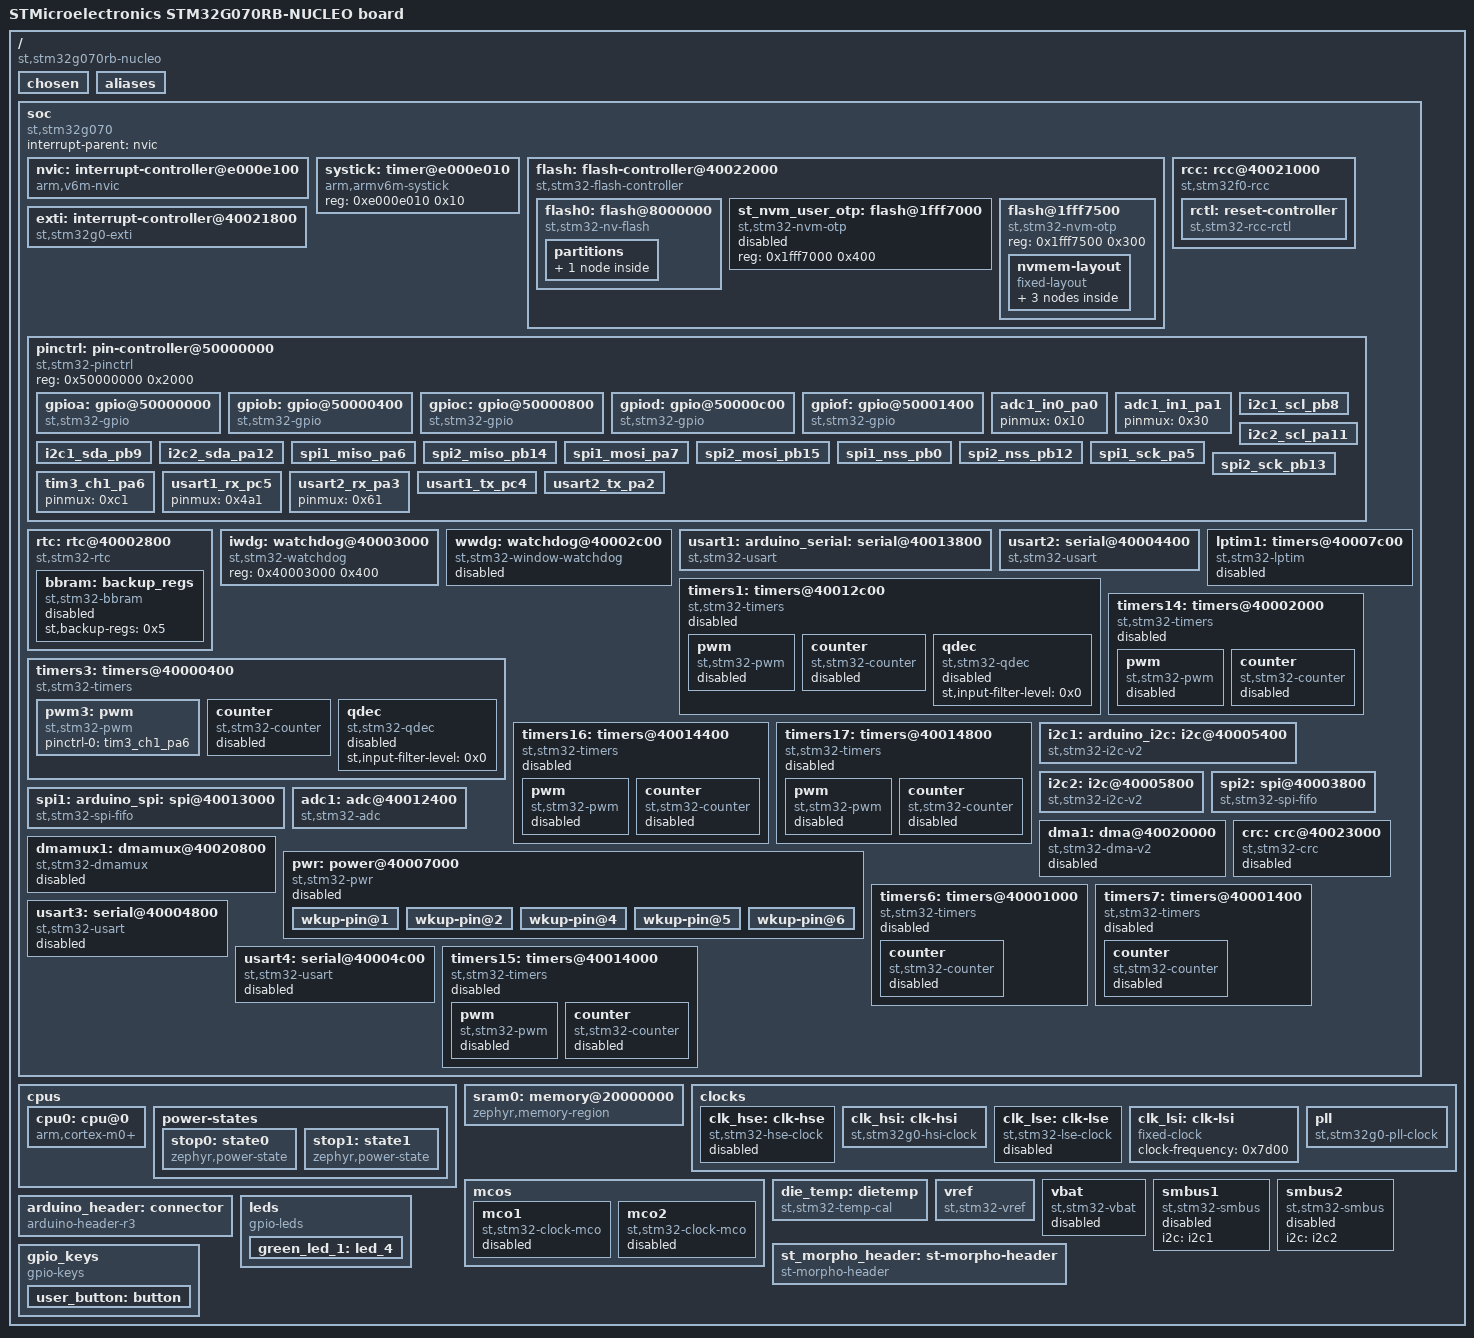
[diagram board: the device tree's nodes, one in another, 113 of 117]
/dts-v1/;

/* node '/' defined in zephyr\dts\common\skeleton.dtsi:9 */
/ {
	#address-cells = < 0x1 >;                              /* in zephyr\dts\common\skeleton.dtsi:10 */
	#size-cells = < 0x1 >;                                 /* in zephyr\dts\common\skeleton.dtsi:11 */
	model = "STMicroelectronics STM32G070RB-NUCLEO board"; /* in zephyr\boards\st\nucleo_g070rb\nucleo_g070rb.dts:15 */
	compatible = "st,stm32g070rb-nucleo";                  /* in zephyr\boards\st\nucleo_g070rb\nucleo_g070rb.dts:16 */

	/* node '/chosen' defined in zephyr\dts\common\skeleton.dtsi:13 */
	chosen {
		zephyr,crc = &crc;                /* in zephyr\dts\arm\st\g0\stm32g0.dtsi:27 */
		zephyr,flash-controller = &flash; /* in zephyr\dts\arm\st\g0\stm32g0.dtsi:28 */
		zephyr,console = &usart2;         /* in zephyr\boards\st\nucleo_g070rb\nucleo_g070rb.dts:19 */
		zephyr,shell-uart = &usart2;      /* in zephyr\boards\st\nucleo_g070rb\nucleo_g070rb.dts:20 */
		zephyr,sram = &sram0;             /* in zephyr\boards\st\nucleo_g070rb\nucleo_g070rb.dts:21 */
		zephyr,flash = &flash0;           /* in zephyr\boards\st\nucleo_g070rb\nucleo_g070rb.dts:22 */
	};

	/* node '/aliases' defined in zephyr\dts\common\skeleton.dtsi:15 */
	aliases {
		led0 = &green_led_1;   /* in zephyr\boards\st\nucleo_g070rb\nucleo_g070rb.dts:45 */
		sw0 = &user_button;    /* in zephyr\boards\st\nucleo_g070rb\nucleo_g070rb.dts:46 */
		watchdog0 = &iwdg;     /* in zephyr\boards\st\nucleo_g070rb\nucleo_g070rb.dts:47 */
		die-temp0 = &die_temp; /* in zephyr\boards\st\nucleo_g070rb\nucleo_g070rb.dts:48 */
		volt-sensor0 = &vref;  /* in zephyr\boards\st\nucleo_g070rb\nucleo_g070rb.dts:49 */
	};

	/* node '/soc' defined in zephyr\dts\arm\armv6-m.dtsi:6 */
	soc {
		#address-cells = < 0x1 >;     /* in zephyr\dts\arm\armv6-m.dtsi:7 */
		#size-cells = < 0x1 >;        /* in zephyr\dts\arm\armv6-m.dtsi:8 */
		interrupt-parent = < &nvic >; /* in zephyr\dts\arm\armv6-m.dtsi:10 */
		ranges;                       /* in zephyr\dts\arm\armv6-m.dtsi:11 */
		compatible = "st,stm32g070",
		             "st,stm32g0",
		             "simple-bus";    /* in zephyr\dts\arm\st\g0\stm32g070.dtsi:12 */

		/* node '/soc/interrupt-controller@e000e100' defined in zephyr\dts\arm\armv6-m.dtsi:13 */
		nvic: interrupt-controller@e000e100 {
			#address-cells = < 0x1 >;            /* in zephyr\dts\arm\armv6-m.dtsi:14 */
			compatible = "arm,v6m-nvic";         /* in zephyr\dts\arm\armv6-m.dtsi:15 */
			reg = < 0xe000e100 0xc00 >;          /* in zephyr\dts\arm\armv6-m.dtsi:16 */
			interrupt-controller;                /* in zephyr\dts\arm\armv6-m.dtsi:17 */
			#interrupt-cells = < 0x2 >;          /* in zephyr\dts\arm\armv6-m.dtsi:18 */
			arm,num-irq-priority-bits = < 0x2 >; /* in zephyr\dts\arm\st\g0\stm32g0.dtsi:623 */
			phandle = < 0x1 >;                   /* in zephyr\dts\arm\armv6-m.dtsi:10 */
		};

		/* node '/soc/timer@e000e010' defined in zephyr\dts\arm\armv6-m.dtsi:21 */
		systick: timer@e000e010 {
			compatible = "arm,armv6m-systick"; /* in zephyr\dts\arm\armv6-m.dtsi:22 */
			reg = < 0xe000e010 0x10 >;         /* in zephyr\dts\arm\armv6-m.dtsi:23 */
		};

		/* node '/soc/flash-controller@40022000' defined in zephyr\dts\arm\st\g0\stm32g0.dtsi:116 */
		flash: flash-controller@40022000 {
			compatible = "st,stm32-flash-controller",
			             "st,stm32g0-flash-controller"; /* in zephyr\dts\arm\st\g0\stm32g0.dtsi:117 */
			reg = < 0x40022000 0x400 >;                 /* in zephyr\dts\arm\st\g0\stm32g0.dtsi:118 */
			interrupts = < 0x3 0x0 >;                   /* in zephyr\dts\arm\st\g0\stm32g0.dtsi:119 */
			clocks = < &rcc 0x38 0x100 >;               /* in zephyr\dts\arm\st\g0\stm32g0.dtsi:120 */
			#address-cells = < 0x1 >;                   /* in zephyr\dts\arm\st\g0\stm32g0.dtsi:122 */
			#size-cells = < 0x1 >;                      /* in zephyr\dts\arm\st\g0\stm32g0.dtsi:123 */
			ranges;                                     /* in zephyr\dts\arm\st\g0\stm32g0.dtsi:124 */

			/* node '/soc/flash-controller@40022000/flash@8000000' defined in zephyr\dts\arm\st\g0\stm32g0.dtsi:126 */
			flash0: flash@8000000 {
				compatible = "st,stm32-nv-flash",
				             "soc-nv-flash";        /* in zephyr\dts\arm\st\g0\stm32g0.dtsi:127 */
				#address-cells = < 0x1 >;           /* in zephyr\dts\arm\st\g0\stm32g0.dtsi:128 */
				#size-cells = < 0x1 >;              /* in zephyr\dts\arm\st\g0\stm32g0.dtsi:129 */
				write-block-size = < 0x8 >;         /* in zephyr\dts\arm\st\g0\stm32g0.dtsi:130 */
				erase-block-size = < 0x800 >;       /* in zephyr\dts\arm\st\g0\stm32g0.dtsi:131 */
				max-erase-time = < 0x28 >;          /* in zephyr\dts\arm\st\g0\stm32g0.dtsi:133 */
				reg = < 0x8000000 0x20000 >;        /* in zephyr\dts\arm\st\g0\stm32g070Xb.dtsi:18 */
				ranges = < 0x0 0x8000000 0x20000 >; /* in zephyr\dts\arm\st\g0\stm32g070Xb.dtsi:19 */

				/* node '/soc/flash-controller@40022000/flash@8000000/partitions' defined in zephyr\boards\st\nucleo_g070rb\nucleo_g070rb.dts:159 */
				partitions {
					#address-cells = < 0x1 >; /* in zephyr\boards\st\nucleo_g070rb\nucleo_g070rb.dts:160 */
					#size-cells = < 0x1 >;    /* in zephyr\boards\st\nucleo_g070rb\nucleo_g070rb.dts:161 */
					ranges;                   /* in zephyr\boards\st\nucleo_g070rb\nucleo_g070rb.dts:162 */

					/* node '/soc/flash-controller@40022000/flash@8000000/partitions/partition@1f000' defined in zephyr\boards\st\nucleo_g070rb\nucleo_g070rb.dts:165 */
					storage_partition: partition@1f000 {
						compatible = "zephyr,mapped-partition"; /* in zephyr\boards\st\nucleo_g070rb\nucleo_g070rb.dts:166 */
						label = "storage";                      /* in zephyr\boards\st\nucleo_g070rb\nucleo_g070rb.dts:167 */
						reg = < 0x1f000 0x1000 >;               /* in zephyr\boards\st\nucleo_g070rb\nucleo_g070rb.dts:168 */
					};
				};
			};

			/* node '/soc/flash-controller@40022000/flash@1fff7000' defined in zephyr\dts\arm\st\g0\stm32g0.dtsi:136 */
			st_nvm_user_otp: flash@1fff7000 {
				compatible = "st,stm32-nvm-otp"; /* in zephyr\dts\arm\st\g0\stm32g0.dtsi:137 */
				reg = < 0x1fff7000 0x400 >;      /* in zephyr\dts\arm\st\g0\stm32g0.dtsi:138 */
				status = "disabled";             /* in zephyr\dts\arm\st\g0\stm32g0.dtsi:139 */
			};

			/* node '/soc/flash-controller@40022000/flash@1fff7500' defined in zephyr\dts\arm\st\g0\stm32g0.dtsi:143 */
			flash@1fff7500 {
				compatible = "st,stm32-nvm-otp"; /* in zephyr\dts\arm\st\g0\stm32g0.dtsi:144 */
				reg = < 0x1fff7500 0x300 >;      /* in zephyr\dts\arm\st\g0\stm32g0.dtsi:145 */

				/* node '/soc/flash-controller@40022000/flash@1fff7500/nvmem-layout' defined in zephyr\dts\arm\st\g0\stm32g0.dtsi:147 */
				nvmem-layout {
					compatible = "fixed-layout"; /* in zephyr\dts\arm\st\g0\stm32g0.dtsi:148 */
					#address-cells = < 0x1 >;    /* in zephyr\dts\arm\st\g0\stm32g0.dtsi:149 */
					#size-cells = < 0x1 >;       /* in zephyr\dts\arm\st\g0\stm32g0.dtsi:150 */

					/* node '/soc/flash-controller@40022000/flash@1fff7500/nvmem-layout/ts-cal1@a8' defined in zephyr\dts\arm\st\g0\stm32g0.dtsi:152 */
					ts_cal1_otp: ts-cal1@a8 {
						reg = < 0xa8 0x2 >;          /* in zephyr\dts\arm\st\g0\stm32g0.dtsi:153 */
						#nvmem-cell-cells = < 0x0 >; /* in zephyr\dts\arm\st\g0\stm32g0.dtsi:154 */
						read-only;                   /* in zephyr\dts\arm\st\g0\stm32g0.dtsi:155 */
						phandle = < 0x1e >;          /* in zephyr\dts\arm\st\g0\stm32g0.dtsi:581 */
					};

					/* node '/soc/flash-controller@40022000/flash@1fff7500/nvmem-layout/vrefint@aa' defined in zephyr\dts\arm\st\g0\stm32g0.dtsi:158 */
					vrefint_otp: vrefint@aa {
						reg = < 0xaa 0x2 >;          /* in zephyr\dts\arm\st\g0\stm32g0.dtsi:159 */
						#nvmem-cell-cells = < 0x0 >; /* in zephyr\dts\arm\st\g0\stm32g0.dtsi:160 */
						read-only;                   /* in zephyr\dts\arm\st\g0\stm32g0.dtsi:161 */
						phandle = < 0x21 >;          /* in zephyr\dts\arm\st\g0\stm32g0.dtsi:592 */
					};

					/* node '/soc/flash-controller@40022000/flash@1fff7500/nvmem-layout/ts-cal2@ca' defined in zephyr\dts\arm\st\g0\stm32g0.dtsi:164 */
					ts_cal2_otp: ts-cal2@ca {
						reg = < 0xca 0x2 >;          /* in zephyr\dts\arm\st\g0\stm32g0.dtsi:165 */
						#nvmem-cell-cells = < 0x0 >; /* in zephyr\dts\arm\st\g0\stm32g0.dtsi:166 */
						read-only;                   /* in zephyr\dts\arm\st\g0\stm32g0.dtsi:167 */
						phandle = < 0x1f >;          /* in zephyr\dts\arm\st\g0\stm32g0.dtsi:581 */
					};
				};
			};
		};

		/* node '/soc/rcc@40021000' defined in zephyr\dts\arm\st\g0\stm32g0.dtsi:173 */
		rcc: rcc@40021000 {
			compatible = "st,stm32f0-rcc";   /* in zephyr\dts\arm\st\g0\stm32g0.dtsi:174 */
			#clock-cells = < 0x2 >;          /* in zephyr\dts\arm\st\g0\stm32g0.dtsi:175 */
			reg = < 0x40021000 0x400 >;      /* in zephyr\dts\arm\st\g0\stm32g0.dtsi:176 */
			clocks = < &pll >;               /* in zephyr\boards\st\nucleo_g070rb\nucleo_g070rb.dts:71 */
			clock-frequency = < 0x3d09000 >; /* in zephyr\boards\st\nucleo_g070rb\nucleo_g070rb.dts:72 */
			ahb-prescaler = < 0x1 >;         /* in zephyr\boards\st\nucleo_g070rb\nucleo_g070rb.dts:73 */
			apb1-prescaler = < 0x1 >;        /* in zephyr\boards\st\nucleo_g070rb\nucleo_g070rb.dts:74 */
			phandle = < 0x2 >;               /* in zephyr\dts\arm\st\g0\stm32g0.dtsi:120 */

			/* node '/soc/rcc@40021000/reset-controller' defined in zephyr\dts\arm\st\g0\stm32g0.dtsi:178 */
			rctl: reset-controller {
				compatible = "st,stm32-rcc-rctl"; /* in zephyr\dts\arm\st\g0\stm32g0.dtsi:179 */
				#reset-cells = < 0x1 >;           /* in zephyr\dts\arm\st\g0\stm32g0.dtsi:180 */
				phandle = < 0x4 >;                /* in zephyr\dts\arm\st\g0\stm32g0.dtsi:285 */
			};
		};

		/* node '/soc/interrupt-controller@40021800' defined in zephyr\dts\arm\st\g0\stm32g0.dtsi:184 */
		exti: interrupt-controller@40021800 {
			compatible = "st,stm32g0-exti",
			             "st,stm32-exti";   /* in zephyr\dts\arm\st\g0\stm32g0.dtsi:185 */
			interrupt-controller;           /* in zephyr\dts\arm\st\g0\stm32g0.dtsi:186 */
			#interrupt-cells = < 0x1 >;     /* in zephyr\dts\arm\st\g0\stm32g0.dtsi:187 */
			#address-cells = < 0x0 >;       /* in zephyr\dts\arm\st\g0\stm32g0.dtsi:188 */
			reg = < 0x40021800 0x400 >;     /* in zephyr\dts\arm\st\g0\stm32g0.dtsi:189 */
			clocks = < &rcc 0x40 0x1 >;     /* in zephyr\dts\arm\st\g0\stm32g0.dtsi:190 */
			num-lines = < 0x20 >;           /* in zephyr\dts\arm\st\g0\stm32g0.dtsi:191 */
			interrupts = < 0x5 0x0 >,
			             < 0x6 0x0 >,
			             < 0x7 0x0 >;       /* in zephyr\dts\arm\st\g0\stm32g0.dtsi:192 */
			interrupt-names = "line0-1",
			                  "line2-3",
			                  "line4-15";   /* in zephyr\dts\arm\st\g0\stm32g0.dtsi:193 */
			line-ranges = < 0x0 0x2 >,
			              < 0x2 0x2 >,
			              < 0x4 0xc >;      /* in zephyr\dts\arm\st\g0\stm32g0.dtsi:194 */
		};

		/* node '/soc/pin-controller@50000000' defined in zephyr\dts\arm\st\g0\stm32g0.dtsi:197 */
		pinctrl: pin-controller@50000000 {
			compatible = "st,stm32-pinctrl"; /* in zephyr\dts\arm\st\g0\stm32g0.dtsi:198 */
			#address-cells = < 0x1 >;        /* in zephyr\dts\arm\st\g0\stm32g0.dtsi:199 */
			#size-cells = < 0x1 >;           /* in zephyr\dts\arm\st\g0\stm32g0.dtsi:200 */
			reg = < 0x50000000 0x2000 >;     /* in zephyr\dts\arm\st\g0\stm32g0.dtsi:201 */

			/* node '/soc/pin-controller@50000000/gpio@50000000' defined in zephyr\dts\arm\st\g0\stm32g0.dtsi:203 */
			gpioa: gpio@50000000 {
				compatible = "st,stm32-gpio"; /* in zephyr\dts\arm\st\g0\stm32g0.dtsi:204 */
				gpio-controller;              /* in zephyr\dts\arm\st\g0\stm32g0.dtsi:205 */
				#gpio-cells = < 0x2 >;        /* in zephyr\dts\arm\st\g0\stm32g0.dtsi:206 */
				reg = < 0x50000000 0x400 >;   /* in zephyr\dts\arm\st\g0\stm32g0.dtsi:207 */
				clocks = < &rcc 0x34 0x1 >;   /* in zephyr\dts\arm\st\g0\stm32g0.dtsi:208 */
				phandle = < 0xf >;            /* in zephyr\boards\st\nucleo_g070rb\nucleo_g070rb.dts:125 */
			};

			/* node '/soc/pin-controller@50000000/gpio@50000400' defined in zephyr\dts\arm\st\g0\stm32g0.dtsi:211 */
			gpiob: gpio@50000400 {
				compatible = "st,stm32-gpio"; /* in zephyr\dts\arm\st\g0\stm32g0.dtsi:212 */
				gpio-controller;              /* in zephyr\dts\arm\st\g0\stm32g0.dtsi:213 */
				#gpio-cells = < 0x2 >;        /* in zephyr\dts\arm\st\g0\stm32g0.dtsi:214 */
				reg = < 0x50000400 0x400 >;   /* in zephyr\dts\arm\st\g0\stm32g0.dtsi:215 */
				clocks = < &rcc 0x34 0x2 >;   /* in zephyr\dts\arm\st\g0\stm32g0.dtsi:216 */
				phandle = < 0xc >;            /* in zephyr\boards\st\nucleo_g070rb\nucleo_g070rb.dts:116 */
			};

			/* node '/soc/pin-controller@50000000/gpio@50000800' defined in zephyr\dts\arm\st\g0\stm32g0.dtsi:219 */
			gpioc: gpio@50000800 {
				compatible = "st,stm32-gpio"; /* in zephyr\dts\arm\st\g0\stm32g0.dtsi:220 */
				gpio-controller;              /* in zephyr\dts\arm\st\g0\stm32g0.dtsi:221 */
				#gpio-cells = < 0x2 >;        /* in zephyr\dts\arm\st\g0\stm32g0.dtsi:222 */
				reg = < 0x50000800 0x400 >;   /* in zephyr\dts\arm\st\g0\stm32g0.dtsi:223 */
				clocks = < &rcc 0x34 0x4 >;   /* in zephyr\dts\arm\st\g0\stm32g0.dtsi:224 */
				phandle = < 0x1a >;           /* in zephyr\dts\arm\st\g0\stm32g0.dtsi:548 */
			};

			/* node '/soc/pin-controller@50000000/gpio@50000c00' defined in zephyr\dts\arm\st\g0\stm32g0.dtsi:227 */
			gpiod: gpio@50000c00 {
				compatible = "st,stm32-gpio"; /* in zephyr\dts\arm\st\g0\stm32g0.dtsi:228 */
				gpio-controller;              /* in zephyr\dts\arm\st\g0\stm32g0.dtsi:229 */
				#gpio-cells = < 0x2 >;        /* in zephyr\dts\arm\st\g0\stm32g0.dtsi:230 */
				reg = < 0x50000c00 0x400 >;   /* in zephyr\dts\arm\st\g0\stm32g0.dtsi:231 */
				clocks = < &rcc 0x34 0x8 >;   /* in zephyr\dts\arm\st\g0\stm32g0.dtsi:232 */
				phandle = < 0x24 >;           /* in zephyr\boards\st\nucleo_g070rb\st_morpho_connector.dtsi:15 */
			};

			/* node '/soc/pin-controller@50000000/gpio@50001400' defined in zephyr\dts\arm\st\g0\stm32g0.dtsi:235 */
			gpiof: gpio@50001400 {
				compatible = "st,stm32-gpio"; /* in zephyr\dts\arm\st\g0\stm32g0.dtsi:236 */
				gpio-controller;              /* in zephyr\dts\arm\st\g0\stm32g0.dtsi:237 */
				#gpio-cells = < 0x2 >;        /* in zephyr\dts\arm\st\g0\stm32g0.dtsi:238 */
				reg = < 0x50001400 0x400 >;   /* in zephyr\dts\arm\st\g0\stm32g0.dtsi:239 */
				clocks = < &rcc 0x34 0x20 >;  /* in zephyr\dts\arm\st\g0\stm32g0.dtsi:240 */
				phandle = < 0x25 >;           /* in zephyr\boards\st\nucleo_g070rb\st_morpho_connector.dtsi:15 */
			};

			/* node '/soc/pin-controller@50000000/adc1_in0_pa0' defined in modules\hal\stm32\dts\st\g0\stm32g070rbtx-pinctrl.dtsi:13 */
			adc1_in0_pa0: adc1_in0_pa0 {
				pinmux = < 0x10 >;  /* in modules\hal\stm32\dts\st\g0\stm32g070rbtx-pinctrl.dtsi:14 */
				phandle = < 0x18 >; /* in zephyr\boards\st\nucleo_g070rb\nucleo_g070rb.dts:146 */
			};

			/* node '/soc/pin-controller@50000000/adc1_in1_pa1' defined in modules\hal\stm32\dts\st\g0\stm32g070rbtx-pinctrl.dtsi:17 */
			adc1_in1_pa1: adc1_in1_pa1 {
				pinmux = < 0x30 >;  /* in modules\hal\stm32\dts\st\g0\stm32g070rbtx-pinctrl.dtsi:18 */
				phandle = < 0x19 >; /* in zephyr\boards\st\nucleo_g070rb\nucleo_g070rb.dts:146 */
			};

			/* node '/soc/pin-controller@50000000/i2c1_scl_pb8' defined in modules\hal\stm32\dts\st\g0\stm32g070rbtx-pinctrl.dtsi:329 */
			i2c1_scl_pb8: i2c1_scl_pb8 {
				pinmux = < 0x306 >; /* in modules\hal\stm32\dts\st\g0\stm32g070rbtx-pinctrl.dtsi:330 */
				bias-pull-up;       /* in modules\hal\stm32\dts\st\g0\stm32g070rbtx-pinctrl.dtsi:331 */
				drive-open-drain;   /* in modules\hal\stm32\dts\st\g0\stm32g070rbtx-pinctrl.dtsi:332 */
				phandle = < 0xa >;  /* in zephyr\boards\st\nucleo_g070rb\nucleo_g070rb.dts:114 */
			};

			/* node '/soc/pin-controller@50000000/i2c2_scl_pa11' defined in modules\hal\stm32\dts\st\g0\stm32g070rbtx-pinctrl.dtsi:335 */
			i2c2_scl_pa11: i2c2_scl_pa11 {
				pinmux = < 0x166 >; /* in modules\hal\stm32\dts\st\g0\stm32g070rbtx-pinctrl.dtsi:336 */
				bias-pull-up;       /* in modules\hal\stm32\dts\st\g0\stm32g070rbtx-pinctrl.dtsi:337 */
				drive-open-drain;   /* in modules\hal\stm32\dts\st\g0\stm32g070rbtx-pinctrl.dtsi:338 */
				phandle = < 0xd >;  /* in zephyr\boards\st\nucleo_g070rb\nucleo_g070rb.dts:123 */
			};

			/* node '/soc/pin-controller@50000000/i2c1_sda_pb9' defined in modules\hal\stm32\dts\st\g0\stm32g070rbtx-pinctrl.dtsi:367 */
			i2c1_sda_pb9: i2c1_sda_pb9 {
				pinmux = < 0x326 >; /* in modules\hal\stm32\dts\st\g0\stm32g070rbtx-pinctrl.dtsi:368 */
				bias-pull-up;       /* in modules\hal\stm32\dts\st\g0\stm32g070rbtx-pinctrl.dtsi:369 */
				drive-open-drain;   /* in modules\hal\stm32\dts\st\g0\stm32g070rbtx-pinctrl.dtsi:370 */
				phandle = < 0xb >;  /* in zephyr\boards\st\nucleo_g070rb\nucleo_g070rb.dts:114 */
			};

			/* node '/soc/pin-controller@50000000/i2c2_sda_pa12' defined in modules\hal\stm32\dts\st\g0\stm32g070rbtx-pinctrl.dtsi:373 */
			i2c2_sda_pa12: i2c2_sda_pa12 {
				pinmux = < 0x186 >; /* in modules\hal\stm32\dts\st\g0\stm32g070rbtx-pinctrl.dtsi:374 */
				bias-pull-up;       /* in modules\hal\stm32\dts\st\g0\stm32g070rbtx-pinctrl.dtsi:375 */
				drive-open-drain;   /* in modules\hal\stm32\dts\st\g0\stm32g070rbtx-pinctrl.dtsi:376 */
				phandle = < 0xe >;  /* in zephyr\boards\st\nucleo_g070rb\nucleo_g070rb.dts:123 */
			};

			/* node '/soc/pin-controller@50000000/spi1_miso_pa6' defined in modules\hal\stm32\dts\st\g0\stm32g070rbtx-pinctrl.dtsi:511 */
			spi1_miso_pa6: spi1_miso_pa6 {
				pinmux = < 0xc0 >;             /* in modules\hal\stm32\dts\st\g0\stm32g070rbtx-pinctrl.dtsi:512 */
				bias-pull-down;                /* in modules\hal\stm32\dts\st\g0\stm32g070rbtx-pinctrl.dtsi:513 */
				slew-rate = "very-high-speed"; /* in modules\hal\stm32\dts\st\g0\stm32g070rbtx-pinctrl.dtsi:514 */
				phandle = < 0x12 >;            /* in zephyr\boards\st\nucleo_g070rb\nucleo_g070rb.dts:132 */
			};

			/* node '/soc/pin-controller@50000000/spi2_miso_pb14' defined in modules\hal\stm32\dts\st\g0\stm32g070rbtx-pinctrl.dtsi:559 */
			spi2_miso_pb14: spi2_miso_pb14 {
				pinmux = < 0x3c0 >;            /* in modules\hal\stm32\dts\st\g0\stm32g070rbtx-pinctrl.dtsi:560 */
				bias-pull-down;                /* in modules\hal\stm32\dts\st\g0\stm32g070rbtx-pinctrl.dtsi:561 */
				slew-rate = "very-high-speed"; /* in modules\hal\stm32\dts\st\g0\stm32g070rbtx-pinctrl.dtsi:562 */
				phandle = < 0x16 >;            /* in zephyr\boards\st\nucleo_g070rb\nucleo_g070rb.dts:139 */
			};

			/* node '/soc/pin-controller@50000000/spi1_mosi_pa7' defined in modules\hal\stm32\dts\st\g0\stm32g070rbtx-pinctrl.dtsi:585 */
			spi1_mosi_pa7: spi1_mosi_pa7 {
				pinmux = < 0xe0 >;             /* in modules\hal\stm32\dts\st\g0\stm32g070rbtx-pinctrl.dtsi:586 */
				bias-pull-down;                /* in modules\hal\stm32\dts\st\g0\stm32g070rbtx-pinctrl.dtsi:587 */
				slew-rate = "very-high-speed"; /* in modules\hal\stm32\dts\st\g0\stm32g070rbtx-pinctrl.dtsi:588 */
				phandle = < 0x13 >;            /* in zephyr\boards\st\nucleo_g070rb\nucleo_g070rb.dts:132 */
			};

			/* node '/soc/pin-controller@50000000/spi2_mosi_pb15' defined in modules\hal\stm32\dts\st\g0\stm32g070rbtx-pinctrl.dtsi:633 */
			spi2_mosi_pb15: spi2_mosi_pb15 {
				pinmux = < 0x3e0 >;            /* in modules\hal\stm32\dts\st\g0\stm32g070rbtx-pinctrl.dtsi:634 */
				bias-pull-down;                /* in modules\hal\stm32\dts\st\g0\stm32g070rbtx-pinctrl.dtsi:635 */
				slew-rate = "very-high-speed"; /* in modules\hal\stm32\dts\st\g0\stm32g070rbtx-pinctrl.dtsi:636 */
				phandle = < 0x17 >;            /* in zephyr\boards\st\nucleo_g070rb\nucleo_g070rb.dts:139 */
			};

			/* node '/soc/pin-controller@50000000/spi1_nss_pb0' defined in modules\hal\stm32\dts\st\g0\stm32g070rbtx-pinctrl.dtsi:665 */
			spi1_nss_pb0: spi1_nss_pb0 {
				pinmux = < 0x200 >;            /* in modules\hal\stm32\dts\st\g0\stm32g070rbtx-pinctrl.dtsi:666 */
				bias-pull-up;                  /* in modules\hal\stm32\dts\st\g0\stm32g070rbtx-pinctrl.dtsi:667 */
				slew-rate = "very-high-speed"; /* in modules\hal\stm32\dts\st\g0\stm32g070rbtx-pinctrl.dtsi:668 */
				phandle = < 0x10 >;            /* in zephyr\boards\st\nucleo_g070rb\nucleo_g070rb.dts:132 */
			};

			/* node '/soc/pin-controller@50000000/spi2_nss_pb12' defined in modules\hal\stm32\dts\st\g0\stm32g070rbtx-pinctrl.dtsi:689 */
			spi2_nss_pb12: spi2_nss_pb12 {
				pinmux = < 0x380 >;            /* in modules\hal\stm32\dts\st\g0\stm32g070rbtx-pinctrl.dtsi:690 */
				bias-pull-up;                  /* in modules\hal\stm32\dts\st\g0\stm32g070rbtx-pinctrl.dtsi:691 */
				slew-rate = "very-high-speed"; /* in modules\hal\stm32\dts\st\g0\stm32g070rbtx-pinctrl.dtsi:692 */
				phandle = < 0x14 >;            /* in zephyr\boards\st\nucleo_g070rb\nucleo_g070rb.dts:139 */
			};

			/* node '/soc/pin-controller@50000000/spi1_sck_pa5' defined in modules\hal\stm32\dts\st\g0\stm32g070rbtx-pinctrl.dtsi:709 */
			spi1_sck_pa5: spi1_sck_pa5 {
				pinmux = < 0xa0 >;             /* in modules\hal\stm32\dts\st\g0\stm32g070rbtx-pinctrl.dtsi:710 */
				bias-pull-down;                /* in modules\hal\stm32\dts\st\g0\stm32g070rbtx-pinctrl.dtsi:711 */
				slew-rate = "very-high-speed"; /* in modules\hal\stm32\dts\st\g0\stm32g070rbtx-pinctrl.dtsi:712 */
				phandle = < 0x11 >;            /* in zephyr\boards\st\nucleo_g070rb\nucleo_g070rb.dts:132 */
			};

			/* node '/soc/pin-controller@50000000/spi2_sck_pb13' defined in modules\hal\stm32\dts\st\g0\stm32g070rbtx-pinctrl.dtsi:745 */
			spi2_sck_pb13: spi2_sck_pb13 {
				pinmux = < 0x3a0 >;            /* in modules\hal\stm32\dts\st\g0\stm32g070rbtx-pinctrl.dtsi:746 */
				bias-pull-down;                /* in modules\hal\stm32\dts\st\g0\stm32g070rbtx-pinctrl.dtsi:747 */
				slew-rate = "very-high-speed"; /* in modules\hal\stm32\dts\st\g0\stm32g070rbtx-pinctrl.dtsi:748 */
				phandle = < 0x15 >;            /* in zephyr\boards\st\nucleo_g070rb\nucleo_g070rb.dts:139 */
			};

			/* node '/soc/pin-controller@50000000/tim3_ch1_pa6' defined in modules\hal\stm32\dts\st\g0\stm32g070rbtx-pinctrl.dtsi:835 */
			tim3_ch1_pa6: tim3_ch1_pa6 {
				pinmux = < 0xc1 >; /* in modules\hal\stm32\dts\st\g0\stm32g070rbtx-pinctrl.dtsi:836 */
				phandle = < 0x9 >; /* in zephyr\boards\st\nucleo_g070rb\nucleo_g070rb.dts:108 */
			};

			/* node '/soc/pin-controller@50000000/usart1_rx_pc5' defined in modules\hal\stm32\dts\st\g0\stm32g070rbtx-pinctrl.dtsi:1108 */
			usart1_rx_pc5: usart1_rx_pc5 {
				pinmux = < 0x4a1 >; /* in modules\hal\stm32\dts\st\g0\stm32g070rbtx-pinctrl.dtsi:1109 */
				phandle = < 0x6 >;  /* in zephyr\boards\st\nucleo_g070rb\nucleo_g070rb.dts:78 */
			};

			/* node '/soc/pin-controller@50000000/usart2_rx_pa3' defined in modules\hal\stm32\dts\st\g0\stm32g070rbtx-pinctrl.dtsi:1112 */
			usart2_rx_pa3: usart2_rx_pa3 {
				pinmux = < 0x61 >; /* in modules\hal\stm32\dts\st\g0\stm32g070rbtx-pinctrl.dtsi:1113 */
				phandle = < 0x8 >; /* in zephyr\boards\st\nucleo_g070rb\nucleo_g070rb.dts:85 */
			};

			/* node '/soc/pin-controller@50000000/usart1_tx_pc4' defined in modules\hal\stm32\dts\st\g0\stm32g070rbtx-pinctrl.dtsi:1168 */
			usart1_tx_pc4: usart1_tx_pc4 {
				pinmux = < 0x481 >; /* in modules\hal\stm32\dts\st\g0\stm32g070rbtx-pinctrl.dtsi:1169 */
				bias-pull-up;       /* in modules\hal\stm32\dts\st\g0\stm32g070rbtx-pinctrl.dtsi:1170 */
				phandle = < 0x5 >;  /* in zephyr\boards\st\nucleo_g070rb\nucleo_g070rb.dts:78 */
			};

			/* node '/soc/pin-controller@50000000/usart2_tx_pa2' defined in modules\hal\stm32\dts\st\g0\stm32g070rbtx-pinctrl.dtsi:1173 */
			usart2_tx_pa2: usart2_tx_pa2 {
				pinmux = < 0x41 >; /* in modules\hal\stm32\dts\st\g0\stm32g070rbtx-pinctrl.dtsi:1174 */
				bias-pull-up;      /* in modules\hal\stm32\dts\st\g0\stm32g070rbtx-pinctrl.dtsi:1175 */
				phandle = < 0x7 >; /* in zephyr\boards\st\nucleo_g070rb\nucleo_g070rb.dts:85 */
			};
		};

		/* node '/soc/rtc@40002800' defined in zephyr\dts\arm\st\g0\stm32g0.dtsi:244 */
		rtc: rtc@40002800 {
			compatible = "st,stm32-rtc";     /* in zephyr\dts\arm\st\g0\stm32g0.dtsi:245 */
			reg = < 0x40002800 0x400 >;      /* in zephyr\dts\arm\st\g0\stm32g0.dtsi:246 */
			interrupts = < 0x2 0x0 >;        /* in zephyr\dts\arm\st\g0\stm32g0.dtsi:247 */
			prescaler = < 0x8000 >;          /* in zephyr\dts\arm\st\g0\stm32g0.dtsi:249 */
			alarms-count = < 0x2 >;          /* in zephyr\dts\arm\st\g0\stm32g0.dtsi:250 */
			alrm-exti-line = < 0x13 >;       /* in zephyr\dts\arm\st\g0\stm32g0.dtsi:251 */
			clocks = < &rcc 0x3c 0x400 >,
			         < &rcc 0x3 0x228005c >; /* in zephyr\boards\st\nucleo_g070rb\nucleo_g070rb.dts:92 */
			status = "okay";                 /* in zephyr\boards\st\nucleo_g070rb\nucleo_g070rb.dts:95 */

			/* node '/soc/rtc@40002800/backup_regs' defined in zephyr\dts\arm\st\g0\stm32g0.dtsi:260 */
			bbram: backup_regs {
				compatible = "st,stm32-bbram"; /* in zephyr\dts\arm\st\g0\stm32g0.dtsi:261 */
				st,backup-regs = < 0x5 >;      /* in zephyr\dts\arm\st\g0\stm32g0.dtsi:262 */
				status = "disabled";           /* in zephyr\dts\arm\st\g0\stm32g0.dtsi:263 */
			};
		};

		/* node '/soc/watchdog@40003000' defined in zephyr\dts\arm\st\g0\stm32g0.dtsi:267 */
		iwdg: watchdog@40003000 {
			compatible = "st,stm32-watchdog"; /* in zephyr\dts\arm\st\g0\stm32g0.dtsi:268 */
			reg = < 0x40003000 0x400 >;       /* in zephyr\dts\arm\st\g0\stm32g0.dtsi:269 */
			status = "okay";                  /* in zephyr\boards\st\nucleo_g070rb\nucleo_g070rb.dts:99 */
		};

		/* node '/soc/watchdog@40002c00' defined in zephyr\dts\arm\st\g0\stm32g0.dtsi:273 */
		wwdg: watchdog@40002c00 {
			compatible = "st,stm32-window-watchdog"; /* in zephyr\dts\arm\st\g0\stm32g0.dtsi:274 */
			reg = < 0x40002c00 0x400 >;              /* in zephyr\dts\arm\st\g0\stm32g0.dtsi:275 */
			clocks = < &rcc 0x3c 0x800 >;            /* in zephyr\dts\arm\st\g0\stm32g0.dtsi:276 */
			interrupts = < 0x0 0x0 >;                /* in zephyr\dts\arm\st\g0\stm32g0.dtsi:277 */
			status = "disabled";                     /* in zephyr\dts\arm\st\g0\stm32g0.dtsi:278 */
		};

		/* node '/soc/serial@40013800' defined in zephyr\dts\arm\st\g0\stm32g0.dtsi:281 */
		usart1: arduino_serial: serial@40013800 {
			compatible = "st,stm32-usart",
			             "st,stm32-uart";                  /* in zephyr\dts\arm\st\g0\stm32g0.dtsi:282 */
			reg = < 0x40013800 0x400 >;                    /* in zephyr\dts\arm\st\g0\stm32g0.dtsi:283 */
			clocks = < &rcc 0x40 0x4000 >;                 /* in zephyr\dts\arm\st\g0\stm32g0.dtsi:284 */
			resets = < &rctl 0x60e >;                      /* in zephyr\dts\arm\st\g0\stm32g0.dtsi:285 */
			interrupts = < 0x1b 0x0 >;                     /* in zephyr\dts\arm\st\g0\stm32g0.dtsi:286 */
			pinctrl-0 = < &usart1_tx_pc4 &usart1_rx_pc5 >; /* in zephyr\boards\st\nucleo_g070rb\nucleo_g070rb.dts:78 */
			pinctrl-names = "default";                     /* in zephyr\boards\st\nucleo_g070rb\nucleo_g070rb.dts:79 */
			current-speed = < 0x1c200 >;                   /* in zephyr\boards\st\nucleo_g070rb\nucleo_g070rb.dts:80 */
			status = "okay";                               /* in zephyr\boards\st\nucleo_g070rb\nucleo_g070rb.dts:81 */
		};

		/* node '/soc/serial@40004400' defined in zephyr\dts\arm\st\g0\stm32g0.dtsi:290 */
		usart2: serial@40004400 {
			compatible = "st,stm32-usart",
			             "st,stm32-uart";                  /* in zephyr\dts\arm\st\g0\stm32g0.dtsi:291 */
			reg = < 0x40004400 0x400 >;                    /* in zephyr\dts\arm\st\g0\stm32g0.dtsi:292 */
			clocks = < &rcc 0x3c 0x20000 >;                /* in zephyr\dts\arm\st\g0\stm32g0.dtsi:293 */
			resets = < &rctl 0x591 >;                      /* in zephyr\dts\arm\st\g0\stm32g0.dtsi:294 */
			interrupts = < 0x1c 0x0 >;                     /* in zephyr\dts\arm\st\g0\stm32g0.dtsi:295 */
			pinctrl-0 = < &usart2_tx_pa2 &usart2_rx_pa3 >; /* in zephyr\boards\st\nucleo_g070rb\nucleo_g070rb.dts:85 */
			pinctrl-names = "default";                     /* in zephyr\boards\st\nucleo_g070rb\nucleo_g070rb.dts:86 */
			current-speed = < 0x1c200 >;                   /* in zephyr\boards\st\nucleo_g070rb\nucleo_g070rb.dts:87 */
			status = "okay";                               /* in zephyr\boards\st\nucleo_g070rb\nucleo_g070rb.dts:88 */
		};

		/* node '/soc/timers@40007c00' defined in zephyr\dts\arm\st\g0\stm32g0.dtsi:299 */
		lptim1: timers@40007c00 {
			compatible = "st,stm32-lptim";     /* in zephyr\dts\arm\st\g0\stm32g0.dtsi:300 */
			clocks = < &rcc 0x3c 0x80000000 >; /* in zephyr\dts\arm\st\g0\stm32g0.dtsi:301 */
			resets = < &rctl 0x59f >;          /* in zephyr\dts\arm\st\g0\stm32g0.dtsi:302 */
			#address-cells = < 0x1 >;          /* in zephyr\dts\arm\st\g0\stm32g0.dtsi:303 */
			#size-cells = < 0x0 >;             /* in zephyr\dts\arm\st\g0\stm32g0.dtsi:304 */
			reg = < 0x40007c00 0x400 >;        /* in zephyr\dts\arm\st\g0\stm32g0.dtsi:305 */
			interrupts = < 0x11 0x0 >;         /* in zephyr\dts\arm\st\g0\stm32g0.dtsi:306 */
			interrupt-names = "wakeup";        /* in zephyr\dts\arm\st\g0\stm32g0.dtsi:307 */
			status = "disabled";               /* in zephyr\dts\arm\st\g0\stm32g0.dtsi:308 */
		};

		/* node '/soc/timers@40012c00' defined in zephyr\dts\arm\st\g0\stm32g0.dtsi:311 */
		timers1: timers@40012c00 {
			compatible = "st,stm32-timers";     /* in zephyr\dts\arm\st\g0\stm32g0.dtsi:312 */
			reg = < 0x40012c00 0x400 >;         /* in zephyr\dts\arm\st\g0\stm32g0.dtsi:313 */
			clocks = < &rcc 0x40 0x800 >,
			         < &rcc 0x9 0xff >;         /* in zephyr\dts\arm\st\g0\stm32g0.dtsi:314 */
			resets = < &rctl 0x60b >;           /* in zephyr\dts\arm\st\g0\stm32g0.dtsi:316 */
			interrupts = < 0xd 0x0 >,
			             < 0xe 0x0 >;           /* in zephyr\dts\arm\st\g0\stm32g0.dtsi:317 */
			interrupt-names = "brk_up_trg_com",
			                  "cc";             /* in zephyr\dts\arm\st\g0\stm32g0.dtsi:318 */
			st,prescaler = < 0x0 >;             /* in zephyr\dts\arm\st\g0\stm32g0.dtsi:319 */
			status = "disabled";                /* in zephyr\dts\arm\st\g0\stm32g0.dtsi:320 */

			/* node '/soc/timers@40012c00/pwm' defined in zephyr\dts\arm\st\g0\stm32g0.dtsi:322 */
			pwm {
				compatible = "st,stm32-pwm"; /* in zephyr\dts\arm\st\g0\stm32g0.dtsi:323 */
				status = "disabled";         /* in zephyr\dts\arm\st\g0\stm32g0.dtsi:324 */
				#pwm-cells = < 0x3 >;        /* in zephyr\dts\arm\st\g0\stm32g0.dtsi:325 */
			};

			/* node '/soc/timers@40012c00/counter' defined in zephyr\dts\arm\st\g0\stm32g0.dtsi:328 */
			counter {
				compatible = "st,stm32-counter"; /* in zephyr\dts\arm\st\g0\stm32g0.dtsi:329 */
				status = "disabled";             /* in zephyr\dts\arm\st\g0\stm32g0.dtsi:330 */
			};

			/* node '/soc/timers@40012c00/qdec' defined in zephyr\dts\arm\st\g0\stm32g0.dtsi:333 */
			qdec {
				compatible = "st,stm32-qdec";    /* in zephyr\dts\arm\st\g0\stm32g0.dtsi:334 */
				st,input-filter-level = < 0x0 >; /* in zephyr\dts\arm\st\g0\stm32g0.dtsi:335 */
				status = "disabled";             /* in zephyr\dts\arm\st\g0\stm32g0.dtsi:336 */
			};
		};

		/* node '/soc/timers@40000400' defined in zephyr\dts\arm\st\g0\stm32g0.dtsi:340 */
		timers3: timers@40000400 {
			compatible = "st,stm32-timers"; /* in zephyr\dts\arm\st\g0\stm32g0.dtsi:341 */
			reg = < 0x40000400 0x400 >;     /* in zephyr\dts\arm\st\g0\stm32g0.dtsi:342 */
			clocks = < &rcc 0x3c 0x2 >,
			         < &rcc 0x9 0xff >;     /* in zephyr\dts\arm\st\g0\stm32g0.dtsi:343 */
			resets = < &rctl 0x581 >;       /* in zephyr\dts\arm\st\g0\stm32g0.dtsi:345 */
			interrupts = < 0x10 0x0 >;      /* in zephyr\dts\arm\st\g0\stm32g0.dtsi:346 */
			interrupt-names = "global";     /* in zephyr\dts\arm\st\g0\stm32g0.dtsi:347 */
			st,prescaler = < 0x2710 >;      /* in zephyr\boards\st\nucleo_g070rb\nucleo_g070rb.dts:103 */
			status = "okay";                /* in zephyr\boards\st\nucleo_g070rb\nucleo_g070rb.dts:104 */

			/* node '/soc/timers@40000400/pwm' defined in zephyr\dts\arm\st\g0\stm32g0.dtsi:351 */
			pwm3: pwm {
				compatible = "st,stm32-pwm";   /* in zephyr\dts\arm\st\g0\stm32g0.dtsi:352 */
				#pwm-cells = < 0x3 >;          /* in zephyr\dts\arm\st\g0\stm32g0.dtsi:354 */
				status = "okay";               /* in zephyr\boards\st\nucleo_g070rb\nucleo_g070rb.dts:107 */
				pinctrl-0 = < &tim3_ch1_pa6 >; /* in zephyr\boards\st\nucleo_g070rb\nucleo_g070rb.dts:108 */
				pinctrl-names = "default";     /* in zephyr\boards\st\nucleo_g070rb\nucleo_g070rb.dts:109 */
			};

			/* node '/soc/timers@40000400/counter' defined in zephyr\dts\arm\st\g0\stm32g0.dtsi:357 */
			counter {
				compatible = "st,stm32-counter"; /* in zephyr\dts\arm\st\g0\stm32g0.dtsi:358 */
				status = "disabled";             /* in zephyr\dts\arm\st\g0\stm32g0.dtsi:359 */
			};

			/* node '/soc/timers@40000400/qdec' defined in zephyr\dts\arm\st\g0\stm32g0.dtsi:362 */
			qdec {
				compatible = "st,stm32-qdec";    /* in zephyr\dts\arm\st\g0\stm32g0.dtsi:363 */
				st,input-filter-level = < 0x0 >; /* in zephyr\dts\arm\st\g0\stm32g0.dtsi:364 */
				status = "disabled";             /* in zephyr\dts\arm\st\g0\stm32g0.dtsi:365 */
			};
		};

		/* node '/soc/timers@40002000' defined in zephyr\dts\arm\st\g0\stm32g0.dtsi:369 */
		timers14: timers@40002000 {
			compatible = "st,stm32-timers"; /* in zephyr\dts\arm\st\g0\stm32g0.dtsi:370 */
			reg = < 0x40002000 0x400 >;     /* in zephyr\dts\arm\st\g0\stm32g0.dtsi:371 */
			clocks = < &rcc 0x40 0x8000 >,
			         < &rcc 0x9 0xff >;     /* in zephyr\dts\arm\st\g0\stm32g0.dtsi:372 */
			resets = < &rctl 0x60f >;       /* in zephyr\dts\arm\st\g0\stm32g0.dtsi:374 */
			interrupts = < 0x13 0x0 >;      /* in zephyr\dts\arm\st\g0\stm32g0.dtsi:375 */
			interrupt-names = "global";     /* in zephyr\dts\arm\st\g0\stm32g0.dtsi:376 */
			st,prescaler = < 0x0 >;         /* in zephyr\dts\arm\st\g0\stm32g0.dtsi:377 */
			status = "disabled";            /* in zephyr\dts\arm\st\g0\stm32g0.dtsi:378 */

			/* node '/soc/timers@40002000/pwm' defined in zephyr\dts\arm\st\g0\stm32g0.dtsi:380 */
			pwm {
				compatible = "st,stm32-pwm"; /* in zephyr\dts\arm\st\g0\stm32g0.dtsi:381 */
				status = "disabled";         /* in zephyr\dts\arm\st\g0\stm32g0.dtsi:382 */
				#pwm-cells = < 0x3 >;        /* in zephyr\dts\arm\st\g0\stm32g0.dtsi:383 */
			};

			/* node '/soc/timers@40002000/counter' defined in zephyr\dts\arm\st\g0\stm32g0.dtsi:386 */
			counter {
				compatible = "st,stm32-counter"; /* in zephyr\dts\arm\st\g0\stm32g0.dtsi:387 */
				status = "disabled";             /* in zephyr\dts\arm\st\g0\stm32g0.dtsi:388 */
			};
		};

		/* node '/soc/timers@40014400' defined in zephyr\dts\arm\st\g0\stm32g0.dtsi:392 */
		timers16: timers@40014400 {
			compatible = "st,stm32-timers"; /* in zephyr\dts\arm\st\g0\stm32g0.dtsi:393 */
			reg = < 0x40014400 0x400 >;     /* in zephyr\dts\arm\st\g0\stm32g0.dtsi:394 */
			clocks = < &rcc 0x40 0x20000 >,
			         < &rcc 0x9 0xff >;     /* in zephyr\dts\arm\st\g0\stm32g0.dtsi:395 */
			resets = < &rctl 0x611 >;       /* in zephyr\dts\arm\st\g0\stm32g0.dtsi:397 */
			interrupts = < 0x15 0x0 >;      /* in zephyr\dts\arm\st\g0\stm32g0.dtsi:398 */
			interrupt-names = "global";     /* in zephyr\dts\arm\st\g0\stm32g0.dtsi:399 */
			st,prescaler = < 0x0 >;         /* in zephyr\dts\arm\st\g0\stm32g0.dtsi:400 */
			status = "disabled";            /* in zephyr\dts\arm\st\g0\stm32g0.dtsi:401 */

			/* node '/soc/timers@40014400/pwm' defined in zephyr\dts\arm\st\g0\stm32g0.dtsi:403 */
			pwm {
				compatible = "st,stm32-pwm"; /* in zephyr\dts\arm\st\g0\stm32g0.dtsi:404 */
				status = "disabled";         /* in zephyr\dts\arm\st\g0\stm32g0.dtsi:405 */
				#pwm-cells = < 0x3 >;        /* in zephyr\dts\arm\st\g0\stm32g0.dtsi:406 */
			};

			/* node '/soc/timers@40014400/counter' defined in zephyr\dts\arm\st\g0\stm32g0.dtsi:409 */
			counter {
				compatible = "st,stm32-counter"; /* in zephyr\dts\arm\st\g0\stm32g0.dtsi:410 */
				status = "disabled";             /* in zephyr\dts\arm\st\g0\stm32g0.dtsi:411 */
			};
		};

		/* node '/soc/timers@40014800' defined in zephyr\dts\arm\st\g0\stm32g0.dtsi:415 */
		timers17: timers@40014800 {
			compatible = "st,stm32-timers"; /* in zephyr\dts\arm\st\g0\stm32g0.dtsi:416 */
			reg = < 0x40014800 0x400 >;     /* in zephyr\dts\arm\st\g0\stm32g0.dtsi:417 */
			clocks = < &rcc 0x40 0x40000 >,
			         < &rcc 0x9 0xff >;     /* in zephyr\dts\arm\st\g0\stm32g0.dtsi:418 */
			resets = < &rctl 0x612 >;       /* in zephyr\dts\arm\st\g0\stm32g0.dtsi:420 */
			interrupts = < 0x16 0x0 >;      /* in zephyr\dts\arm\st\g0\stm32g0.dtsi:421 */
			interrupt-names = "global";     /* in zephyr\dts\arm\st\g0\stm32g0.dtsi:422 */
			st,prescaler = < 0x0 >;         /* in zephyr\dts\arm\st\g0\stm32g0.dtsi:423 */
			status = "disabled";            /* in zephyr\dts\arm\st\g0\stm32g0.dtsi:424 */

			/* node '/soc/timers@40014800/pwm' defined in zephyr\dts\arm\st\g0\stm32g0.dtsi:426 */
			pwm {
				compatible = "st,stm32-pwm"; /* in zephyr\dts\arm\st\g0\stm32g0.dtsi:427 */
				status = "disabled";         /* in zephyr\dts\arm\st\g0\stm32g0.dtsi:428 */
				#pwm-cells = < 0x3 >;        /* in zephyr\dts\arm\st\g0\stm32g0.dtsi:429 */
			};

			/* node '/soc/timers@40014800/counter' defined in zephyr\dts\arm\st\g0\stm32g0.dtsi:432 */
			counter {
				compatible = "st,stm32-counter"; /* in zephyr\dts\arm\st\g0\stm32g0.dtsi:433 */
				status = "disabled";             /* in zephyr\dts\arm\st\g0\stm32g0.dtsi:434 */
			};
		};

		/* node '/soc/i2c@40005400' defined in zephyr\dts\arm\st\g0\stm32g0.dtsi:438 */
		i2c1: arduino_i2c: i2c@40005400 {
			compatible = "st,stm32-i2c-v2";              /* in zephyr\dts\arm\st\g0\stm32g0.dtsi:439 */
			#address-cells = < 0x1 >;                    /* in zephyr\dts\arm\st\g0\stm32g0.dtsi:441 */
			#size-cells = < 0x0 >;                       /* in zephyr\dts\arm\st\g0\stm32g0.dtsi:442 */
			reg = < 0x40005400 0x400 >;                  /* in zephyr\dts\arm\st\g0\stm32g0.dtsi:443 */
			clocks = < &rcc 0x3c 0x200000 >;             /* in zephyr\dts\arm\st\g0\stm32g0.dtsi:444 */
			interrupts = < 0x17 0x0 >;                   /* in zephyr\dts\arm\st\g0\stm32g0.dtsi:445 */
			interrupt-names = "combined";                /* in zephyr\dts\arm\st\g0\stm32g0.dtsi:446 */
			pinctrl-0 = < &i2c1_scl_pb8 &i2c1_sda_pb9 >; /* in zephyr\boards\st\nucleo_g070rb\nucleo_g070rb.dts:114 */
			pinctrl-names = "default";                   /* in zephyr\boards\st\nucleo_g070rb\nucleo_g070rb.dts:115 */
			scl-gpios = < &gpiob 0x8 0x0 >;              /* in zephyr\boards\st\nucleo_g070rb\nucleo_g070rb.dts:116 */
			sda-gpios = < &gpiob 0x9 0x0 >;              /* in zephyr\boards\st\nucleo_g070rb\nucleo_g070rb.dts:117 */
			status = "okay";                             /* in zephyr\boards\st\nucleo_g070rb\nucleo_g070rb.dts:118 */
			clock-frequency = < 0x61a80 >;               /* in zephyr\boards\st\nucleo_g070rb\nucleo_g070rb.dts:119 */
			phandle = < 0x22 >;                          /* in zephyr\dts\arm\st\g0\stm32g0.dtsi:609 */
		};

		/* node '/soc/i2c@40005800' defined in zephyr\dts\arm\st\g0\stm32g0.dtsi:450 */
		i2c2: i2c@40005800 {
			compatible = "st,stm32-i2c-v2";                /* in zephyr\dts\arm\st\g0\stm32g0.dtsi:451 */
			#address-cells = < 0x1 >;                      /* in zephyr\dts\arm\st\g0\stm32g0.dtsi:453 */
			#size-cells = < 0x0 >;                         /* in zephyr\dts\arm\st\g0\stm32g0.dtsi:454 */
			reg = < 0x40005800 0x400 >;                    /* in zephyr\dts\arm\st\g0\stm32g0.dtsi:455 */
			clocks = < &rcc 0x3c 0x400000 >;               /* in zephyr\dts\arm\st\g0\stm32g0.dtsi:456 */
			interrupts = < 0x18 0x0 >;                     /* in zephyr\dts\arm\st\g0\stm32g0.dtsi:457 */
			interrupt-names = "combined";                  /* in zephyr\dts\arm\st\g0\stm32g0.dtsi:458 */
			pinctrl-0 = < &i2c2_scl_pa11 &i2c2_sda_pa12 >; /* in zephyr\boards\st\nucleo_g070rb\nucleo_g070rb.dts:123 */
			pinctrl-names = "default";                     /* in zephyr\boards\st\nucleo_g070rb\nucleo_g070rb.dts:124 */
			scl-gpios = < &gpioa 0xb 0x0 >;                /* in zephyr\boards\st\nucleo_g070rb\nucleo_g070rb.dts:125 */
			sda-gpios = < &gpioa 0xc 0x0 >;                /* in zephyr\boards\st\nucleo_g070rb\nucleo_g070rb.dts:126 */
			status = "okay";                               /* in zephyr\boards\st\nucleo_g070rb\nucleo_g070rb.dts:127 */
			clock-frequency = < 0x61a80 >;                 /* in zephyr\boards\st\nucleo_g070rb\nucleo_g070rb.dts:128 */
			phandle = < 0x23 >;                            /* in zephyr\dts\arm\st\g0\stm32g0.dtsi:617 */
		};

		/* node '/soc/spi@40013000' defined in zephyr\dts\arm\st\g0\stm32g0.dtsi:462 */
		spi1: arduino_spi: spi@40013000 {
			compatible = "st,stm32-spi-fifo",
			             "st,stm32-spi";                                               /* in zephyr\dts\arm\st\g0\stm32g0.dtsi:463 */
			#address-cells = < 0x1 >;                                                  /* in zephyr\dts\arm\st\g0\stm32g0.dtsi:464 */
			#size-cells = < 0x0 >;                                                     /* in zephyr\dts\arm\st\g0\stm32g0.dtsi:465 */
			reg = < 0x40013000 0x400 >;                                                /* in zephyr\dts\arm\st\g0\stm32g0.dtsi:466 */
			clocks = < &rcc 0x40 0x1000 >;                                             /* in zephyr\dts\arm\st\g0\stm32g0.dtsi:467 */
			interrupts = < 0x19 0x0 >;                                                 /* in zephyr\dts\arm\st\g0\stm32g0.dtsi:468 */
			st,spi-data-width = "full-4-to-16-bit";                                    /* in zephyr\dts\arm\st\g0\stm32g0.dtsi:469 */
			pinctrl-0 = < &spi1_nss_pb0 &spi1_sck_pa5 &spi1_miso_pa6 &spi1_mosi_pa7 >; /* in zephyr\boards\st\nucleo_g070rb\nucleo_g070rb.dts:132 */
			pinctrl-names = "default";                                                 /* in zephyr\boards\st\nucleo_g070rb\nucleo_g070rb.dts:134 */
			status = "okay";                                                           /* in zephyr\boards\st\nucleo_g070rb\nucleo_g070rb.dts:135 */
		};

		/* node '/soc/spi@40003800' defined in zephyr\dts\arm\st\g0\stm32g0.dtsi:473 */
		spi2: spi@40003800 {
			compatible = "st,stm32-spi-fifo",
			             "st,stm32-spi";                                                   /* in zephyr\dts\arm\st\g0\stm32g0.dtsi:474 */
			#address-cells = < 0x1 >;                                                      /* in zephyr\dts\arm\st\g0\stm32g0.dtsi:475 */
			#size-cells = < 0x0 >;                                                         /* in zephyr\dts\arm\st\g0\stm32g0.dtsi:476 */
			reg = < 0x40003800 0x400 >;                                                    /* in zephyr\dts\arm\st\g0\stm32g0.dtsi:477 */
			clocks = < &rcc 0x3c 0x4000 >;                                                 /* in zephyr\dts\arm\st\g0\stm32g0.dtsi:478 */
			interrupts = < 0x1a 0x0 >;                                                     /* in zephyr\dts\arm\st\g0\stm32g0.dtsi:479 */
			st,spi-data-width = "full-4-to-16-bit";                                        /* in zephyr\dts\arm\st\g0\stm32g0.dtsi:480 */
			pinctrl-0 = < &spi2_nss_pb12 &spi2_sck_pb13 &spi2_miso_pb14 &spi2_mosi_pb15 >; /* in zephyr\boards\st\nucleo_g070rb\nucleo_g070rb.dts:139 */
			pinctrl-names = "default";                                                     /* in zephyr\boards\st\nucleo_g070rb\nucleo_g070rb.dts:141 */
			status = "okay";                                                               /* in zephyr\boards\st\nucleo_g070rb\nucleo_g070rb.dts:142 */
		};

		/* node '/soc/adc@40012400' defined in zephyr\dts\arm\st\g0\stm32g0.dtsi:484 */
		adc1: adc@40012400 {
			compatible = "st,stm32-adc";                              /* in zephyr\dts\arm\st\g0\stm32g0.dtsi:485 */
			reg = < 0x40012400 0x400 >;                               /* in zephyr\dts\arm\st\g0\stm32g0.dtsi:486 */
			clocks = < &rcc 0x40 0x100000 >;                          /* in zephyr\dts\arm\st\g0\stm32g0.dtsi:487 */
			clock-names = "adcx";                                     /* in zephyr\dts\arm\st\g0\stm32g0.dtsi:488 */
			interrupts = < 0xc 0x0 >;                                 /* in zephyr\dts\arm\st\g0\stm32g0.dtsi:489 */
			#io-channel-cells = < 0x1 >;                              /* in zephyr\dts\arm\st\g0\stm32g0.dtsi:490 */
			st,adc-resolutions = < 0xc 0xa 0x8 0x6 >;                 /* in zephyr\dts\arm\st\g0\stm32g0.dtsi:491 */
			sampling-times = < 0x3 0x5 0x8 0xd 0x14 0x28 0x50 0xa1 >; /* in zephyr\dts\arm\st\g0\stm32g0.dtsi:498 */
			num-sampling-time-common-channels = < 0x2 >;              /* in zephyr\dts\arm\st\g0\stm32g0.dtsi:499 */
			st,adc-sequencer = "fixed";                               /* in zephyr\dts\arm\st\g0\stm32g0.dtsi:500 */
			st,adc-oversampler = "minimal";                           /* in zephyr\dts\arm\st\g0\stm32g0.dtsi:501 */
			st,adc-internal-regulator = "startup-sw-delay";           /* in zephyr\dts\arm\st\g0\stm32g0.dtsi:502 */
			pinctrl-0 = < &adc1_in0_pa0 &adc1_in1_pa1 >;              /* in zephyr\boards\st\nucleo_g070rb\nucleo_g070rb.dts:146 */
			pinctrl-names = "default";                                /* in zephyr\boards\st\nucleo_g070rb\nucleo_g070rb.dts:147 */
			st,adc-clock-source = "SYNC";                             /* in zephyr\boards\st\nucleo_g070rb\nucleo_g070rb.dts:148 */
			st,adc-prescaler = < 0x4 >;                               /* in zephyr\boards\st\nucleo_g070rb\nucleo_g070rb.dts:149 */
			status = "okay";                                          /* in zephyr\boards\st\nucleo_g070rb\nucleo_g070rb.dts:150 */
			vref-mv = < 0xce4 >;                                      /* in zephyr\boards\st\nucleo_g070rb\nucleo_g070rb.dts:151 */
			phandle = < 0x20 >;                                       /* in zephyr\dts\arm\st\g0\stm32g0.dtsi:586 */
		};

		/* node '/soc/dma@40020000' defined in zephyr\dts\arm\st\g0\stm32g0.dtsi:506 */
		dma1: dma@40020000 {
			compatible = "st,stm32-dma-v2";                                           /* in zephyr\dts\arm\st\g0\stm32g0.dtsi:507 */
			#dma-cells = < 0x3 >;                                                     /* in zephyr\dts\arm\st\g0\stm32g0.dtsi:508 */
			reg = < 0x40020000 0x400 >;                                               /* in zephyr\dts\arm\st\g0\stm32g0.dtsi:509 */
			clocks = < &rcc 0x38 0x1 >;                                               /* in zephyr\dts\arm\st\g0\stm32g0.dtsi:511 */
			dma-offset = < 0x0 >;                                                     /* in zephyr\dts\arm\st\g0\stm32g0.dtsi:513 */
			status = "disabled";                                                      /* in zephyr\dts\arm\st\g0\stm32g0.dtsi:514 */
			interrupts = < 0x9 0x0 0xa 0x0 0xa 0x0 0xb 0x0 0xb 0x0 0xb 0x0 0xb 0x0 >; /* in zephyr\dts\arm\st\g0\stm32g050.dtsi:48 */
			dma-requests = < 0x7 >;                                                   /* in zephyr\dts\arm\st\g0\stm32g050.dtsi:49 */
		};

		/* node '/soc/dmamux@40020800' defined in zephyr\dts\arm\st\g0\stm32g0.dtsi:518 */
		dmamux1: dmamux@40020800 {
			compatible = "st,stm32-dmamux"; /* in zephyr\dts\arm\st\g0\stm32g0.dtsi:519 */
			#dma-cells = < 0x3 >;           /* in zephyr\dts\arm\st\g0\stm32g0.dtsi:520 */
			reg = < 0x40020800 0x800 >;     /* in zephyr\dts\arm\st\g0\stm32g0.dtsi:521 */
			interrupts = < 0xb 0x0 >;       /* in zephyr\dts\arm\st\g0\stm32g0.dtsi:522 */
			dma-generators = < 0x4 >;       /* in zephyr\dts\arm\st\g0\stm32g0.dtsi:524 */
			status = "disabled";            /* in zephyr\dts\arm\st\g0\stm32g0.dtsi:526 */
			dma-channels = < 0x7 >;         /* in zephyr\dts\arm\st\g0\stm32g050.dtsi:53 */
			dma-requests = < 0x35 >;        /* in zephyr\dts\arm\st\g0\stm32g070.dtsi:56 */
		};

		/* node '/soc/power@40007000' defined in zephyr\dts\arm\st\g0\stm32g0.dtsi:529 */
		pwr: power@40007000 {
			compatible = "st,stm32-pwr"; /* in zephyr\dts\arm\st\g0\stm32g0.dtsi:530 */
			reg = < 0x40007000 0x400 >;  /* in zephyr\dts\arm\st\g0\stm32g0.dtsi:531 */
			status = "disabled";         /* in zephyr\dts\arm\st\g0\stm32g0.dtsi:532 */
			wkup-pins-nb = < 0x6 >;      /* in zephyr\dts\arm\st\g0\stm32g0.dtsi:534 */
			wkup-pins-pol;               /* in zephyr\dts\arm\st\g0\stm32g0.dtsi:535 */
			wkup-pins-pupd;              /* in zephyr\dts\arm\st\g0\stm32g0.dtsi:536 */
			#address-cells = < 0x1 >;    /* in zephyr\dts\arm\st\g0\stm32g0.dtsi:538 */
			#size-cells = < 0x0 >;       /* in zephyr\dts\arm\st\g0\stm32g0.dtsi:539 */

			/* node '/soc/power@40007000/wkup-pin@1' defined in zephyr\dts\arm\st\g0\stm32g0.dtsi:541 */
			wkup-pin@1 {
				reg = < 0x1 >;                   /* in zephyr\dts\arm\st\g0\stm32g0.dtsi:542 */
				wkup-gpios = < &gpioa 0x0 0x1 >; /* in zephyr\dts\arm\st\g0\stm32g0.dtsi:543 */
			};

			/* node '/soc/power@40007000/wkup-pin@2' defined in zephyr\dts\arm\st\g0\stm32g0.dtsi:546 */
			wkup-pin@2 {
				reg = < 0x2 >;                   /* in zephyr\dts\arm\st\g0\stm32g0.dtsi:547 */
				wkup-gpios = < &gpioa 0x4 0x1 >,
				             < &gpioc 0xd 0x1 >; /* in zephyr\dts\arm\st\g0\stm32g0.dtsi:548 */
			};

			/* node '/soc/power@40007000/wkup-pin@4' defined in zephyr\dts\arm\st\g0\stm32g0.dtsi:554 */
			wkup-pin@4 {
				reg = < 0x4 >;                   /* in zephyr\dts\arm\st\g0\stm32g0.dtsi:555 */
				wkup-gpios = < &gpioa 0x2 0x1 >; /* in zephyr\dts\arm\st\g0\stm32g0.dtsi:556 */
			};

			/* node '/soc/power@40007000/wkup-pin@5' defined in zephyr\dts\arm\st\g0\stm32g0.dtsi:559 */
			wkup-pin@5 {
				reg = < 0x5 >;                   /* in zephyr\dts\arm\st\g0\stm32g0.dtsi:560 */
				wkup-gpios = < &gpioc 0x5 0x1 >; /* in zephyr\dts\arm\st\g0\stm32g0.dtsi:561 */
			};

			/* node '/soc/power@40007000/wkup-pin@6' defined in zephyr\dts\arm\st\g0\stm32g0.dtsi:564 */
			wkup-pin@6 {
				reg = < 0x6 >;                   /* in zephyr\dts\arm\st\g0\stm32g0.dtsi:565 */
				wkup-gpios = < &gpiob 0x5 0x1 >; /* in zephyr\dts\arm\st\g0\stm32g0.dtsi:566 */
			};
		};

		/* node '/soc/crc@40023000' defined in zephyr\dts\arm\st\g0\stm32g0.dtsi:570 */
		crc: crc@40023000 {
			compatible = "st,stm32-crc";   /* in zephyr\dts\arm\st\g0\stm32g0.dtsi:571 */
			reg = < 0x40023000 0x400 >;    /* in zephyr\dts\arm\st\g0\stm32g0.dtsi:572 */
			clocks = < &rcc 0x38 0x1000 >; /* in zephyr\dts\arm\st\g0\stm32g0.dtsi:573 */
			resets = < &rctl 0x50c >;      /* in zephyr\dts\arm\st\g0\stm32g0.dtsi:574 */
			status = "disabled";           /* in zephyr\dts\arm\st\g0\stm32g0.dtsi:575 */
		};

		/* node '/soc/timers@40001000' defined in zephyr\dts\arm\st\g0\stm32g050.dtsi:13 */
		timers6: timers@40001000 {
			compatible = "st,stm32-timers"; /* in zephyr\dts\arm\st\g0\stm32g050.dtsi:14 */
			reg = < 0x40001000 0x400 >;     /* in zephyr\dts\arm\st\g0\stm32g050.dtsi:15 */
			clocks = < &rcc 0x3c 0x10 >,
			         < &rcc 0x9 0xff >;     /* in zephyr\dts\arm\st\g0\stm32g050.dtsi:16 */
			resets = < &rctl 0x584 >;       /* in zephyr\dts\arm\st\g0\stm32g050.dtsi:18 */
			interrupts = < 0x11 0x0 >;      /* in zephyr\dts\arm\st\g0\stm32g050.dtsi:19 */
			interrupt-names = "global";     /* in zephyr\dts\arm\st\g0\stm32g050.dtsi:20 */
			st,prescaler = < 0x0 >;         /* in zephyr\dts\arm\st\g0\stm32g050.dtsi:21 */
			status = "disabled";            /* in zephyr\dts\arm\st\g0\stm32g050.dtsi:22 */

			/* node '/soc/timers@40001000/counter' defined in zephyr\dts\arm\st\g0\stm32g050.dtsi:24 */
			counter {
				compatible = "st,stm32-counter"; /* in zephyr\dts\arm\st\g0\stm32g050.dtsi:25 */
				status = "disabled";             /* in zephyr\dts\arm\st\g0\stm32g050.dtsi:26 */
			};
		};

		/* node '/soc/timers@40001400' defined in zephyr\dts\arm\st\g0\stm32g050.dtsi:30 */
		timers7: timers@40001400 {
			compatible = "st,stm32-timers"; /* in zephyr\dts\arm\st\g0\stm32g050.dtsi:31 */
			reg = < 0x40001400 0x400 >;     /* in zephyr\dts\arm\st\g0\stm32g050.dtsi:32 */
			clocks = < &rcc 0x3c 0x20 >,
			         < &rcc 0x9 0xff >;     /* in zephyr\dts\arm\st\g0\stm32g050.dtsi:33 */
			resets = < &rctl 0x585 >;       /* in zephyr\dts\arm\st\g0\stm32g050.dtsi:35 */
			interrupts = < 0x12 0x0 >;      /* in zephyr\dts\arm\st\g0\stm32g050.dtsi:36 */
			interrupt-names = "global";     /* in zephyr\dts\arm\st\g0\stm32g050.dtsi:37 */
			st,prescaler = < 0x0 >;         /* in zephyr\dts\arm\st\g0\stm32g050.dtsi:38 */
			status = "disabled";            /* in zephyr\dts\arm\st\g0\stm32g050.dtsi:39 */

			/* node '/soc/timers@40001400/counter' defined in zephyr\dts\arm\st\g0\stm32g050.dtsi:41 */
			counter {
				compatible = "st,stm32-counter"; /* in zephyr\dts\arm\st\g0\stm32g050.dtsi:42 */
				status = "disabled";             /* in zephyr\dts\arm\st\g0\stm32g050.dtsi:43 */
			};
		};

		/* node '/soc/serial@40004800' defined in zephyr\dts\arm\st\g0\stm32g070.dtsi:14 */
		usart3: serial@40004800 {
			compatible = "st,stm32-usart",
			             "st,stm32-uart";   /* in zephyr\dts\arm\st\g0\stm32g070.dtsi:15 */
			reg = < 0x40004800 0x400 >;     /* in zephyr\dts\arm\st\g0\stm32g070.dtsi:16 */
			clocks = < &rcc 0x3c 0x40000 >; /* in zephyr\dts\arm\st\g0\stm32g070.dtsi:17 */
			resets = < &rctl 0x592 >;       /* in zephyr\dts\arm\st\g0\stm32g070.dtsi:18 */
			interrupts = < 0x1d 0x0 >;      /* in zephyr\dts\arm\st\g0\stm32g070.dtsi:19 */
			status = "disabled";            /* in zephyr\dts\arm\st\g0\stm32g070.dtsi:20 */
		};

		/* node '/soc/serial@40004c00' defined in zephyr\dts\arm\st\g0\stm32g070.dtsi:23 */
		usart4: serial@40004c00 {
			compatible = "st,stm32-usart",
			             "st,stm32-uart";   /* in zephyr\dts\arm\st\g0\stm32g070.dtsi:24 */
			reg = < 0x40004c00 0x400 >;     /* in zephyr\dts\arm\st\g0\stm32g070.dtsi:25 */
			clocks = < &rcc 0x3c 0x80000 >; /* in zephyr\dts\arm\st\g0\stm32g070.dtsi:26 */
			resets = < &rctl 0x593 >;       /* in zephyr\dts\arm\st\g0\stm32g070.dtsi:27 */
			interrupts = < 0x1d 0x0 >;      /* in zephyr\dts\arm\st\g0\stm32g070.dtsi:28 */
			status = "disabled";            /* in zephyr\dts\arm\st\g0\stm32g070.dtsi:29 */
		};

		/* node '/soc/timers@40014000' defined in zephyr\dts\arm\st\g0\stm32g070.dtsi:32 */
		timers15: timers@40014000 {
			compatible = "st,stm32-timers"; /* in zephyr\dts\arm\st\g0\stm32g070.dtsi:33 */
			reg = < 0x40014000 0x400 >;     /* in zephyr\dts\arm\st\g0\stm32g070.dtsi:34 */
			clocks = < &rcc 0x40 0x10000 >,
			         < &rcc 0x9 0xff >;     /* in zephyr\dts\arm\st\g0\stm32g070.dtsi:35 */
			resets = < &rctl 0x610 >;       /* in zephyr\dts\arm\st\g0\stm32g070.dtsi:37 */
			interrupts = < 0x14 0x0 >;      /* in zephyr\dts\arm\st\g0\stm32g070.dtsi:38 */
			interrupt-names = "global";     /* in zephyr\dts\arm\st\g0\stm32g070.dtsi:39 */
			st,prescaler = < 0x0 >;         /* in zephyr\dts\arm\st\g0\stm32g070.dtsi:40 */
			status = "disabled";            /* in zephyr\dts\arm\st\g0\stm32g070.dtsi:41 */

			/* node '/soc/timers@40014000/pwm' defined in zephyr\dts\arm\st\g0\stm32g070.dtsi:43 */
			pwm {
				compatible = "st,stm32-pwm"; /* in zephyr\dts\arm\st\g0\stm32g070.dtsi:44 */
				status = "disabled";         /* in zephyr\dts\arm\st\g0\stm32g070.dtsi:45 */
				#pwm-cells = < 0x3 >;        /* in zephyr\dts\arm\st\g0\stm32g070.dtsi:46 */
			};

			/* node '/soc/timers@40014000/counter' defined in zephyr\dts\arm\st\g0\stm32g070.dtsi:49 */
			counter {
				compatible = "st,stm32-counter"; /* in zephyr\dts\arm\st\g0\stm32g070.dtsi:50 */
				status = "disabled";             /* in zephyr\dts\arm\st\g0\stm32g070.dtsi:51 */
			};
		};
	};

	/* node '/cpus' defined in zephyr\dts\arm\st\g0\stm32g0.dtsi:31 */
	cpus {
		#address-cells = < 0x1 >; /* in zephyr\dts\arm\st\g0\stm32g0.dtsi:32 */
		#size-cells = < 0x0 >;    /* in zephyr\dts\arm\st\g0\stm32g0.dtsi:33 */

		/* node '/cpus/cpu@0' defined in zephyr\dts\arm\st\g0\stm32g0.dtsi:35 */
		cpu0: cpu@0 {
			device_type = "cpu";                  /* in zephyr\dts\arm\st\g0\stm32g0.dtsi:36 */
			compatible = "arm,cortex-m0+";        /* in zephyr\dts\arm\st\g0\stm32g0.dtsi:37 */
			reg = < 0x0 >;                        /* in zephyr\dts\arm\st\g0\stm32g0.dtsi:38 */
			cpu-power-states = < &stop0 &stop1 >; /* in zephyr\dts\arm\st\g0\stm32g0.dtsi:39 */
		};

		/* node '/cpus/power-states' defined in zephyr\dts\arm\st\g0\stm32g0.dtsi:42 */
		power-states {

			/* node '/cpus/power-states/state0' defined in zephyr\dts\arm\st\g0\stm32g0.dtsi:43 */
			stop0: state0 {
				compatible = "zephyr,power-state";    /* in zephyr\dts\arm\st\g0\stm32g0.dtsi:44 */
				power-state-name = "suspend-to-idle"; /* in zephyr\dts\arm\st\g0\stm32g0.dtsi:45 */
				substate-id = < 0x1 >;                /* in zephyr\dts\arm\st\g0\stm32g0.dtsi:46 */
				min-residency-us = < 0x14 >;          /* in zephyr\dts\arm\st\g0\stm32g0.dtsi:47 */
				phandle = < 0x1b >;                   /* in zephyr\dts\arm\st\g0\stm32g0.dtsi:39 */
			};

			/* node '/cpus/power-states/state1' defined in zephyr\dts\arm\st\g0\stm32g0.dtsi:50 */
			stop1: state1 {
				compatible = "zephyr,power-state";    /* in zephyr\dts\arm\st\g0\stm32g0.dtsi:51 */
				power-state-name = "suspend-to-idle"; /* in zephyr\dts\arm\st\g0\stm32g0.dtsi:52 */
				substate-id = < 0x2 >;                /* in zephyr\dts\arm\st\g0\stm32g0.dtsi:53 */
				min-residency-us = < 0x64 >;          /* in zephyr\dts\arm\st\g0\stm32g0.dtsi:54 */
				phandle = < 0x1c >;                   /* in zephyr\dts\arm\st\g0\stm32g0.dtsi:39 */
			};
		};
	};

	/* node '/memory@20000000' defined in zephyr\dts\arm\st\g0\stm32g0.dtsi:59 */
	sram0: memory@20000000 {
		compatible = "zephyr,memory-region",
		             "mmio-sram";            /* in zephyr\dts\arm\st\g0\stm32g0.dtsi:60 */
		zephyr,memory-region = "SRAM0";      /* in zephyr\dts\arm\st\g0\stm32g0.dtsi:61 */
		reg = < 0x20000000 0x9000 >;         /* in zephyr\dts\arm\st\g0\stm32g070Xb.dtsi:12 */
	};

	/* node '/clocks' defined in zephyr\dts\arm\st\g0\stm32g0.dtsi:64 */
	clocks {

		/* node '/clocks/clk-hse' defined in zephyr\dts\arm\st\g0\stm32g0.dtsi:65 */
		clk_hse: clk-hse {
			#clock-cells = < 0x0 >;            /* in zephyr\dts\arm\st\g0\stm32g0.dtsi:66 */
			compatible = "st,stm32-hse-clock"; /* in zephyr\dts\arm\st\g0\stm32g0.dtsi:67 */
			status = "disabled";               /* in zephyr\dts\arm\st\g0\stm32g0.dtsi:68 */
		};

		/* node '/clocks/clk-hsi' defined in zephyr\dts\arm\st\g0\stm32g0.dtsi:71 */
		clk_hsi: clk-hsi {
			#clock-cells = < 0x0 >;              /* in zephyr\dts\arm\st\g0\stm32g0.dtsi:72 */
			compatible = "st,stm32g0-hsi-clock"; /* in zephyr\dts\arm\st\g0\stm32g0.dtsi:73 */
			hsi-div = < 0x1 >;                   /* in zephyr\dts\arm\st\g0\stm32g0.dtsi:74 */
			clock-frequency = < 0xf42400 >;      /* in zephyr\dts\arm\st\g0\stm32g0.dtsi:75 */
			status = "okay";                     /* in zephyr\boards\st\nucleo_g070rb\nucleo_g070rb.dts:58 */
			phandle = < 0x1d >;                  /* in zephyr\boards\st\nucleo_g070rb\nucleo_g070rb.dts:66 */
		};

		/* node '/clocks/clk-lse' defined in zephyr\dts\arm\st\g0\stm32g0.dtsi:79 */
		clk_lse: clk-lse {
			#clock-cells = < 0x0 >;            /* in zephyr\dts\arm\st\g0\stm32g0.dtsi:80 */
			compatible = "st,stm32-lse-clock"; /* in zephyr\dts\arm\st\g0\stm32g0.dtsi:81 */
			clock-frequency = < 0x8000 >;      /* in zephyr\dts\arm\st\g0\stm32g0.dtsi:82 */
			driving-capability = < 0x0 >;      /* in zephyr\dts\arm\st\g0\stm32g0.dtsi:83 */
			status = "disabled";               /* in zephyr\dts\arm\st\g0\stm32g0.dtsi:84 */
		};

		/* node '/clocks/clk-lsi' defined in zephyr\dts\arm\st\g0\stm32g0.dtsi:87 */
		clk_lsi: clk-lsi {
			#clock-cells = < 0x0 >;       /* in zephyr\dts\arm\st\g0\stm32g0.dtsi:88 */
			compatible = "fixed-clock";   /* in zephyr\dts\arm\st\g0\stm32g0.dtsi:89 */
			clock-frequency = < 0x7d00 >; /* in zephyr\dts\arm\st\g0\stm32g0.dtsi:90 */
			status = "okay";              /* in zephyr\boards\st\nucleo_g070rb\nucleo_g070rb.dts:54 */
		};

		/* node '/clocks/pll' defined in zephyr\dts\arm\st\g0\stm32g0.dtsi:94 */
		pll: pll {
			#clock-cells = < 0x0 >;              /* in zephyr\dts\arm\st\g0\stm32g0.dtsi:95 */
			compatible = "st,stm32g0-pll-clock"; /* in zephyr\dts\arm\st\g0\stm32g0.dtsi:96 */
			div-m = < 0x1 >;                     /* in zephyr\boards\st\nucleo_g070rb\nucleo_g070rb.dts:62 */
			mul-n = < 0x8 >;                     /* in zephyr\boards\st\nucleo_g070rb\nucleo_g070rb.dts:63 */
			div-p = < 0x2 >;                     /* in zephyr\boards\st\nucleo_g070rb\nucleo_g070rb.dts:64 */
			div-r = < 0x2 >;                     /* in zephyr\boards\st\nucleo_g070rb\nucleo_g070rb.dts:65 */
			clocks = < &clk_hsi >;               /* in zephyr\boards\st\nucleo_g070rb\nucleo_g070rb.dts:66 */
			status = "okay";                     /* in zephyr\boards\st\nucleo_g070rb\nucleo_g070rb.dts:67 */
			phandle = < 0x3 >;                   /* in zephyr\boards\st\nucleo_g070rb\nucleo_g070rb.dts:71 */
		};
	};

	/* node '/mcos' defined in zephyr\dts\arm\st\g0\stm32g0.dtsi:101 */
	mcos {

		/* node '/mcos/mco1' defined in zephyr\dts\arm\st\g0\stm32g0.dtsi:102 */
		mco1: mco1 {
			compatible = "st,stm32-clock-mco"; /* in zephyr\dts\arm\st\g0\stm32g0.dtsi:103 */
			clock-names = "clksel";            /* in zephyr\dts\arm\st\g0\stm32g0.dtsi:104 */
			status = "disabled";               /* in zephyr\dts\arm\st\g0\stm32g0.dtsi:105 */
		};

		/* node '/mcos/mco2' defined in zephyr\dts\arm\st\g0\stm32g0.dtsi:108 */
		mco2: mco2 {
			compatible = "st,stm32-clock-mco"; /* in zephyr\dts\arm\st\g0\stm32g0.dtsi:109 */
			clock-names = "clksel";            /* in zephyr\dts\arm\st\g0\stm32g0.dtsi:110 */
			status = "disabled";               /* in zephyr\dts\arm\st\g0\stm32g0.dtsi:111 */
		};
	};

	/* node '/dietemp' defined in zephyr\dts\arm\st\g0\stm32g0.dtsi:579 */
	die_temp: dietemp {
		compatible = "st,stm32-temp-cal"; /* in zephyr\dts\arm\st\g0\stm32g0.dtsi:580 */
		nvmem-cells = < &ts_cal1_otp >,
		              < &ts_cal2_otp >;   /* in zephyr\dts\arm\st\g0\stm32g0.dtsi:581 */
		nvmem-cell-names = "TS_CAL1",
		                   "TS_CAL2";     /* in zephyr\dts\arm\st\g0\stm32g0.dtsi:582 */
		ts-cal1-temp = < 0x1e >;          /* in zephyr\dts\arm\st\g0\stm32g0.dtsi:583 */
		ts-cal2-temp = < 0x82 >;          /* in zephyr\dts\arm\st\g0\stm32g0.dtsi:584 */
		ts-cal-vrefanalog = < 0xbb8 >;    /* in zephyr\dts\arm\st\g0\stm32g0.dtsi:585 */
		io-channels = < &adc1 0xc >;      /* in zephyr\dts\arm\st\g0\stm32g0.dtsi:586 */
		status = "okay";                  /* in zephyr\boards\st\nucleo_g070rb\nucleo_g070rb.dts:155 */
	};

	/* node '/vref' defined in zephyr\dts\arm\st\g0\stm32g0.dtsi:590 */
	vref: vref {
		compatible = "st,stm32-vref";   /* in zephyr\dts\arm\st\g0\stm32g0.dtsi:591 */
		nvmem-cells = < &vrefint_otp >; /* in zephyr\dts\arm\st\g0\stm32g0.dtsi:592 */
		vrefint-cal-mv = < 0xbb8 >;     /* in zephyr\dts\arm\st\g0\stm32g0.dtsi:593 */
		io-channels = < &adc1 0xd >;    /* in zephyr\dts\arm\st\g0\stm32g0.dtsi:594 */
		status = "okay";                /* in zephyr\boards\st\nucleo_g070rb\nucleo_g070rb.dts:174 */
	};

	/* node '/vbat' defined in zephyr\dts\arm\st\g0\stm32g0.dtsi:598 */
	vbat: vbat {
		compatible = "st,stm32-vbat"; /* in zephyr\dts\arm\st\g0\stm32g0.dtsi:599 */
		ratio = < 0x3 >;              /* in zephyr\dts\arm\st\g0\stm32g0.dtsi:600 */
		io-channels = < &adc1 0xe >;  /* in zephyr\dts\arm\st\g0\stm32g0.dtsi:601 */
		status = "disabled";          /* in zephyr\dts\arm\st\g0\stm32g0.dtsi:602 */
	};

	/* node '/smbus1' defined in zephyr\dts\arm\st\g0\stm32g0.dtsi:605 */
	smbus1: smbus1 {
		compatible = "st,stm32-smbus"; /* in zephyr\dts\arm\st\g0\stm32g0.dtsi:606 */
		#address-cells = < 0x1 >;      /* in zephyr\dts\arm\st\g0\stm32g0.dtsi:607 */
		#size-cells = < 0x0 >;         /* in zephyr\dts\arm\st\g0\stm32g0.dtsi:608 */
		i2c = < &i2c1 >;               /* in zephyr\dts\arm\st\g0\stm32g0.dtsi:609 */
		status = "disabled";           /* in zephyr\dts\arm\st\g0\stm32g0.dtsi:610 */
	};

	/* node '/smbus2' defined in zephyr\dts\arm\st\g0\stm32g0.dtsi:613 */
	smbus2: smbus2 {
		compatible = "st,stm32-smbus"; /* in zephyr\dts\arm\st\g0\stm32g0.dtsi:614 */
		#address-cells = < 0x1 >;      /* in zephyr\dts\arm\st\g0\stm32g0.dtsi:615 */
		#size-cells = < 0x0 >;         /* in zephyr\dts\arm\st\g0\stm32g0.dtsi:616 */
		i2c = < &i2c2 >;               /* in zephyr\dts\arm\st\g0\stm32g0.dtsi:617 */
		status = "disabled";           /* in zephyr\dts\arm\st\g0\stm32g0.dtsi:618 */
	};

	/* node '/connector' defined in zephyr\boards\st\nucleo_g070rb\arduino_r3_connector.dtsi:10 */
	arduino_header: connector {
		compatible = "arduino-header-r3";          /* in zephyr\boards\st\nucleo_g070rb\arduino_r3_connector.dtsi:11 */
		#gpio-cells = < 0x2 >;                     /* in zephyr\boards\st\nucleo_g070rb\arduino_r3_connector.dtsi:12 */
		gpio-map-mask = < 0xffffffff 0xffffffc0 >; /* in zephyr\boards\st\nucleo_g070rb\arduino_r3_connector.dtsi:13 */
		gpio-map-pass-thru = < 0x0 0x3f >;         /* in zephyr\boards\st\nucleo_g070rb\arduino_r3_connector.dtsi:14 */
		gpio-map = < 0x0 0x0 &gpioa 0x0 0x0 >,
		           < 0x1 0x0 &gpioa 0x1 0x0 >,
		           < 0x2 0x0 &gpioa 0x4 0x0 >,
		           < 0x3 0x0 &gpiob 0x1 0x0 >,
		           < 0x4 0x0 &gpiob 0xb 0x0 >,
		           < 0x5 0x0 &gpiob 0xc 0x0 >,
		           < 0x6 0x0 &gpioc 0x5 0x0 >,
		           < 0x7 0x0 &gpioc 0x4 0x0 >,
		           < 0x8 0x0 &gpioa 0xa 0x0 >,
		           < 0x9 0x0 &gpiob 0x3 0x0 >,
		           < 0xa 0x0 &gpiob 0x5 0x0 >,
		           < 0xb 0x0 &gpiob 0x4 0x0 >,
		           < 0xc 0x0 &gpiob 0xe 0x0 >,
		           < 0xd 0x0 &gpioa 0x8 0x0 >,
		           < 0xe 0x0 &gpioa 0x9 0x0 >,
		           < 0xf 0x0 &gpioc 0x7 0x0 >,
		           < 0x10 0x0 &gpiob 0x0 0x0 >,
		           < 0x11 0x0 &gpioa 0x7 0x0 >,
		           < 0x12 0x0 &gpioa 0x6 0x0 >,
		           < 0x13 0x0 &gpioa 0x5 0x0 >,
		           < 0x14 0x0 &gpiob 0x9 0x0 >,
		           < 0x15 0x0 &gpiob 0x8 0x0 >;    /* in zephyr\boards\st\nucleo_g070rb\arduino_r3_connector.dtsi:15 */
	};

	/* node '/st-morpho-header' defined in zephyr\boards\st\nucleo_g070rb\st_morpho_connector.dtsi:10 */
	st_morpho_header: st-morpho-header {
		compatible = "st-morpho-header";        /* in zephyr\boards\st\nucleo_g070rb\st_morpho_connector.dtsi:11 */
		#gpio-cells = < 0x2 >;                  /* in zephyr\boards\st\nucleo_g070rb\st_morpho_connector.dtsi:12 */
		gpio-map-mask = < 0xff 0x0 >;           /* in zephyr\boards\st\nucleo_g070rb\st_morpho_connector.dtsi:13 */
		gpio-map-pass-thru = < 0x0 0x7f >;      /* in zephyr\boards\st\nucleo_g070rb\st_morpho_connector.dtsi:14 */
		gpio-map = < 0x0 0x0 &gpioc 0xa 0x0 >,
		           < 0x1 0x0 &gpioc 0xb 0x0 >,
		           < 0x2 0x0 &gpioc 0xc 0x0 >,
		           < 0x3 0x0 &gpiod 0x2 0x0 >,
		           < 0x6 0x0 &gpioa 0xe 0x0 >,
		           < 0x8 0x0 &gpiod 0x0 0x0 >,
		           < 0x9 0x0 &gpiod 0x1 0x0 >,
		           < 0xa 0x0 &gpiod 0x3 0x0 >,
		           < 0xc 0x0 &gpioa 0xd 0x0 >,
		           < 0xe 0x0 &gpiod 0x4 0x0 >,
		           < 0x10 0x0 &gpioa 0xf 0x0 >,
		           < 0x14 0x0 &gpiob 0x7 0x0 >,
		           < 0x16 0x0 &gpioc 0xd 0x0 >,
		           < 0x18 0x0 &gpioc 0xe 0x0 >,
		           < 0x19 0x0 &gpiod 0x5 0x0 >,
		           < 0x1a 0x0 &gpioc 0xf 0x0 >,
		           < 0x1b 0x0 &gpioa 0x0 0x0 >,
		           < 0x1c 0x0 &gpiof 0x0 0x0 >,
		           < 0x1d 0x0 &gpioa 0x1 0x0 >,
		           < 0x1e 0x0 &gpiof 0x1 0x0 >,
		           < 0x1f 0x0 &gpioa 0x4 0x0 >,
		           < 0x21 0x0 &gpiob 0x1 0x0 >,
		           < 0x22 0x0 &gpioc 0x2 0x0 >,
		           < 0x23 0x0 &gpiob 0xb 0x0 >,
		           < 0x24 0x0 &gpioc 0x3 0x0 >,
		           < 0x25 0x0 &gpiob 0xc 0x0 >,
		           < 0x48 0x0 &gpioc 0x9 0x0 >,
		           < 0x49 0x0 &gpioc 0x8 0x0 >,
		           < 0x4a 0x0 &gpiob 0x8 0x0 >,
		           < 0x4b 0x0 &gpioc 0x6 0x0 >,
		           < 0x4c 0x0 &gpiob 0x9 0x0 >,
		           < 0x4d 0x0 &gpioa 0x3 0x0 >,
		           < 0x51 0x0 &gpiod 0x6 0x0 >,
		           < 0x52 0x0 &gpioa 0x5 0x0 >,
		           < 0x53 0x0 &gpioa 0xc 0x0 >,
		           < 0x54 0x0 &gpioa 0x6 0x0 >,
		           < 0x55 0x0 &gpioa 0xb 0x0 >,
		           < 0x56 0x0 &gpioa 0x7 0x0 >,
		           < 0x57 0x0 &gpioc 0x1 0x0 >,
		           < 0x58 0x0 &gpiob 0x0 0x0 >,
		           < 0x59 0x0 &gpioc 0x0 0x0 >,
		           < 0x5a 0x0 &gpioc 0x7 0x0 >,
		           < 0x5c 0x0 &gpioa 0x9 0x0 >,
		           < 0x5d 0x0 &gpiob 0x2 0x0 >,
		           < 0x5e 0x0 &gpioa 0x8 0x0 >,
		           < 0x5f 0x0 &gpiob 0x6 0x0 >,
		           < 0x60 0x0 &gpiob 0xe 0x0 >,
		           < 0x61 0x0 &gpiob 0xf 0x0 >,
		           < 0x62 0x0 &gpiob 0x4 0x0 >,
		           < 0x63 0x0 &gpiob 0xa 0x0 >,
		           < 0x64 0x0 &gpiob 0x5 0x0 >,
		           < 0x65 0x0 &gpiob 0xd 0x0 >,
		           < 0x66 0x0 &gpiob 0x3 0x0 >,
		           < 0x68 0x0 &gpioa 0xa 0x0 >,
		           < 0x69 0x0 &gpioa 0x2 0x0 >,
		           < 0x6a 0x0 &gpioc 0x4 0x0 >,
		           < 0x6b 0x0 &gpiod 0x8 0x0 >,
		           < 0x6c 0x0 &gpioc 0x5 0x0 >,
		           < 0x6d 0x0 &gpiod 0x9 0x0 >; /* in zephyr\boards\st\nucleo_g070rb\st_morpho_connector.dtsi:15 */
	};

	/* node '/leds' defined in zephyr\boards\st\nucleo_g070rb\nucleo_g070rb.dts:25 */
	leds: leds {
		compatible = "gpio-leds"; /* in zephyr\boards\st\nucleo_g070rb\nucleo_g070rb.dts:26 */

		/* node '/leds/led_4' defined in zephyr\boards\st\nucleo_g070rb\nucleo_g070rb.dts:28 */
		green_led_1: led_4 {
			gpios = < &gpioa 0x5 0x0 >; /* in zephyr\boards\st\nucleo_g070rb\nucleo_g070rb.dts:29 */
			label = "User LD4";         /* in zephyr\boards\st\nucleo_g070rb\nucleo_g070rb.dts:30 */
		};
	};

	/* node '/gpio_keys' defined in zephyr\boards\st\nucleo_g070rb\nucleo_g070rb.dts:34 */
	gpio_keys {
		compatible = "gpio-keys"; /* in zephyr\boards\st\nucleo_g070rb\nucleo_g070rb.dts:35 */

		/* node '/gpio_keys/button' defined in zephyr\boards\st\nucleo_g070rb\nucleo_g070rb.dts:37 */
		user_button: button {
			label = "User";             /* in zephyr\boards\st\nucleo_g070rb\nucleo_g070rb.dts:38 */
			gpios = < &gpioc 0xd 0x1 >; /* in zephyr\boards\st\nucleo_g070rb\nucleo_g070rb.dts:39 */
			zephyr,code = < 0xb >;      /* in zephyr\boards\st\nucleo_g070rb\nucleo_g070rb.dts:40 */
		};
	};
};
